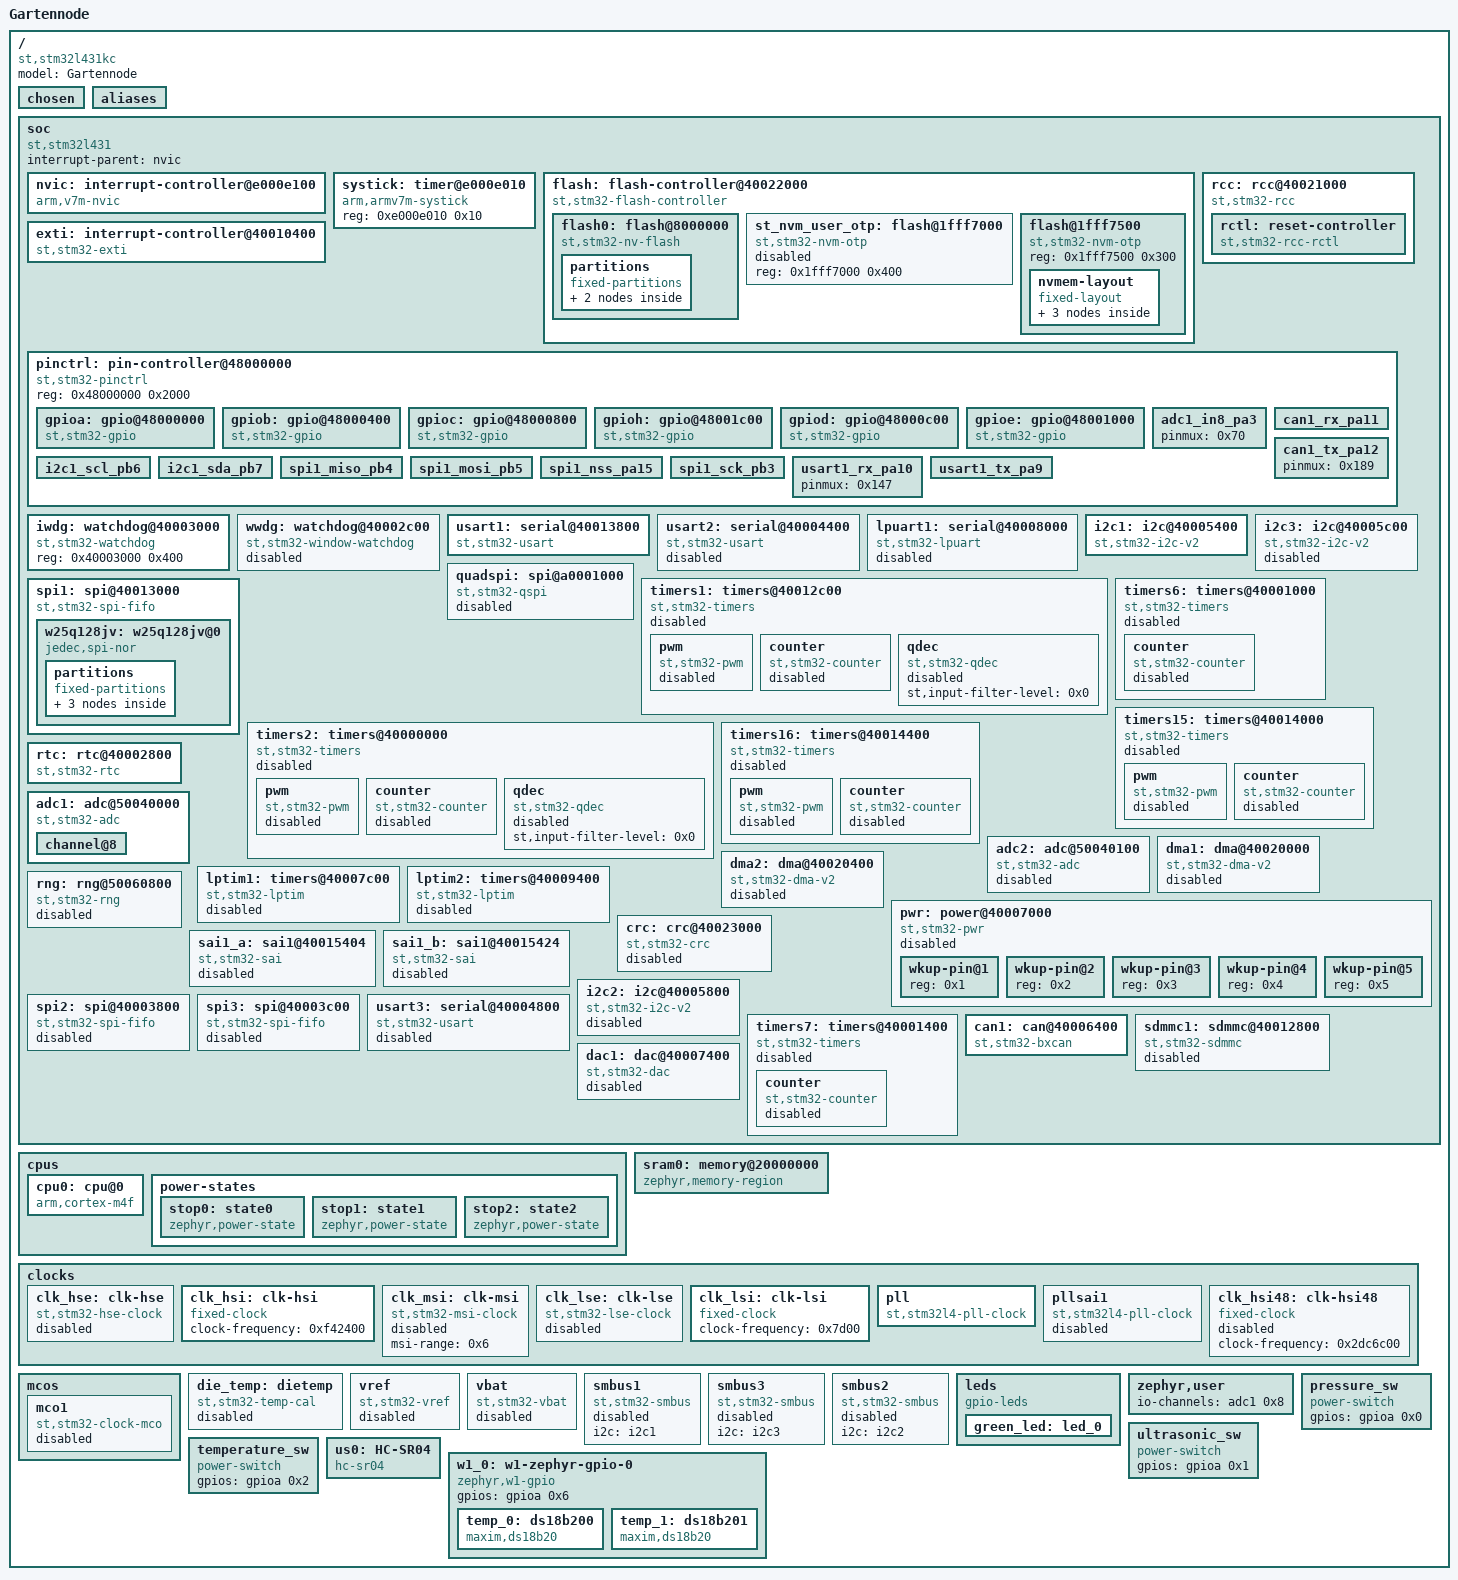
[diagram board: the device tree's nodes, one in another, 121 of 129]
/dts-v1/;

/* node '/' defined in zephyr/dts/common/skeleton.dtsi:9 */
/ {
	#address-cells = < 0x1 >;      /* in zephyr/dts/common/skeleton.dtsi:10 */
	#size-cells = < 0x1 >;         /* in zephyr/dts/common/skeleton.dtsi:11 */
	model = "Gartennode";          /* in application/boards/st/gartennode/gartennode.dts:6 */
	compatible = "st,stm32l431kc"; /* in application/boards/st/gartennode/gartennode.dts:7 */

	/* node '/chosen' defined in zephyr/dts/common/skeleton.dtsi:13 */
	chosen {
		zephyr,crc = &crc;                              /* in zephyr/dts/arm/st/l4/stm32l4.dtsi:25 */
		zephyr,entropy = &rng;                          /* in zephyr/dts/arm/st/l4/stm32l4.dtsi:26 */
		zephyr,flash-controller = &flash;               /* in zephyr/dts/arm/st/l4/stm32l4.dtsi:27 */
		zephyr,console = &usart1;                       /* in application/boards/st/gartennode/gartennode.dts:10 */
		zephyr,shell-uart = &usart1;                    /* in application/boards/st/gartennode/gartennode.dts:11 */
		zephyr,sram = &sram0;                           /* in application/boards/st/gartennode/gartennode.dts:12 */
		zephyr,flash = &flash0;                         /* in application/boards/st/gartennode/gartennode.dts:13 */
		zephyr,code-partition = &slot0_partition;       /* in application/boards/st/gartennode/gartennode.dts:14 */
		zephyr,canbus = &can1;                          /* in application/boards/st/gartennode/gartennode.dts:15 */
		zephyr,settings-partition = &storage_partition; /* in application/boards/st/gartennode/gartennode.dts:16 */
	};

	/* node '/aliases' defined in zephyr/dts/common/skeleton.dtsi:15 */
	aliases {
		led0 = &green_led;      /* in application/boards/st/gartennode/gartennode.dts:28 */
		green-led = &green_led; /* in application/boards/gartennode.overlay:34 */
	};

	/* node '/soc' defined in zephyr/dts/arm/armv7-m.dtsi:6 */
	soc {
		#address-cells = < 0x1 >;     /* in zephyr/dts/arm/armv7-m.dtsi:7 */
		#size-cells = < 0x1 >;        /* in zephyr/dts/arm/armv7-m.dtsi:8 */
		interrupt-parent = < &nvic >; /* in zephyr/dts/arm/armv7-m.dtsi:10 */
		ranges;                       /* in zephyr/dts/arm/armv7-m.dtsi:11 */
		compatible = "st,stm32l431",
		             "st,stm32l4",
		             "simple-bus";    /* in zephyr/dts/arm/st/l4/stm32l431.dtsi:21 */

		/* node '/soc/interrupt-controller@e000e100' defined in zephyr/dts/arm/armv7-m.dtsi:13 */
		nvic: interrupt-controller@e000e100 {
			#address-cells = < 0x1 >;            /* in zephyr/dts/arm/armv7-m.dtsi:14 */
			compatible = "arm,v7m-nvic";         /* in zephyr/dts/arm/armv7-m.dtsi:15 */
			reg = < 0xe000e100 0xc00 >;          /* in zephyr/dts/arm/armv7-m.dtsi:16 */
			interrupt-controller;                /* in zephyr/dts/arm/armv7-m.dtsi:17 */
			#interrupt-cells = < 0x2 >;          /* in zephyr/dts/arm/armv7-m.dtsi:18 */
			arm,num-irq-priority-bits = < 0x4 >; /* in zephyr/dts/arm/st/l4/stm32l4.dtsi:645 */
			phandle = < 0x1 >;                   /* in zephyr/dts/arm/armv7-m.dtsi:10 */
		};

		/* node '/soc/timer@e000e010' defined in zephyr/dts/arm/armv7-m.dtsi:21 */
		systick: timer@e000e010 {
			compatible = "arm,armv7m-systick"; /* in zephyr/dts/arm/armv7-m.dtsi:22 */
			reg = < 0xe000e010 0x10 >;         /* in zephyr/dts/arm/armv7-m.dtsi:23 */
		};

		/* node '/soc/flash-controller@40022000' defined in zephyr/dts/arm/st/l4/stm32l4.dtsi:128 */
		flash: flash-controller@40022000 {
			compatible = "st,stm32-flash-controller",
			             "st,stm32l4-flash-controller"; /* in zephyr/dts/arm/st/l4/stm32l4.dtsi:129 */
			reg = < 0x40022000 0x400 >;                 /* in zephyr/dts/arm/st/l4/stm32l4.dtsi:130 */
			interrupts = < 0x4 0x0 >;                   /* in zephyr/dts/arm/st/l4/stm32l4.dtsi:131 */
			clocks = < &rcc 0x48 0x100 >;               /* in zephyr/dts/arm/st/l4/stm32l4.dtsi:132 */
			#address-cells = < 0x1 >;                   /* in zephyr/dts/arm/st/l4/stm32l4.dtsi:134 */
			#size-cells = < 0x1 >;                      /* in zephyr/dts/arm/st/l4/stm32l4.dtsi:135 */

			/* node '/soc/flash-controller@40022000/flash@8000000' defined in zephyr/dts/arm/st/l4/stm32l4.dtsi:137 */
			flash0: flash@8000000 {
				compatible = "st,stm32-nv-flash",
				             "soc-nv-flash";      /* in zephyr/dts/arm/st/l4/stm32l4.dtsi:138 */
				write-block-size = < 0x8 >;       /* in zephyr/dts/arm/st/l4/stm32l4.dtsi:140 */
				erase-block-size = < 0x800 >;     /* in zephyr/dts/arm/st/l4/stm32l4.dtsi:141 */
				max-erase-time = < 0x19 >;        /* in zephyr/dts/arm/st/l4/stm32l4.dtsi:143 */
				reg = < 0x8000000 0x40000 >;      /* in application/boards/st/gartennode/stm32l431Xc.dtsi:18 */

				/* node '/soc/flash-controller@40022000/flash@8000000/partitions' defined in application/boards/st/gartennode/gartennode.dts:128 */
				partitions {
					compatible = "fixed-partitions"; /* in application/boards/st/gartennode/gartennode.dts:129 */
					#address-cells = < 0x1 >;        /* in application/boards/st/gartennode/gartennode.dts:130 */
					#size-cells = < 0x1 >;           /* in application/boards/st/gartennode/gartennode.dts:131 */

					/* node '/soc/flash-controller@40022000/flash@8000000/partitions/partition@0' defined in application/boards/st/gartennode/gartennode.dts:137 */
					boot_partition: partition@0 {
						label = "mcuboot";     /* in application/boards/st/gartennode/gartennode.dts:138 */
						reg = < 0x0 0x10000 >; /* in application/boards/st/gartennode/gartennode.dts:139 */
						read-only;             /* in application/boards/st/gartennode/gartennode.dts:140 */
					};

					/* node '/soc/flash-controller@40022000/flash@8000000/partitions/partition@10000' defined in application/boards/st/gartennode/gartennode.dts:146 */
					slot0_partition: partition@10000 {
						label = "image-0";         /* in application/boards/st/gartennode/gartennode.dts:147 */
						reg = < 0x10000 0x30000 >; /* in application/boards/st/gartennode/gartennode.dts:148 */
					};
				};
			};

			/* node '/soc/flash-controller@40022000/flash@1fff7000' defined in zephyr/dts/arm/st/l4/stm32l4.dtsi:146 */
			st_nvm_user_otp: flash@1fff7000 {
				compatible = "st,stm32-nvm-otp"; /* in zephyr/dts/arm/st/l4/stm32l4.dtsi:147 */
				reg = < 0x1fff7000 0x400 >;      /* in zephyr/dts/arm/st/l4/stm32l4.dtsi:148 */
				status = "disabled";             /* in zephyr/dts/arm/st/l4/stm32l4.dtsi:149 */
			};

			/* node '/soc/flash-controller@40022000/flash@1fff7500' defined in zephyr/dts/arm/st/l4/stm32l4.dtsi:153 */
			flash@1fff7500 {
				compatible = "st,stm32-nvm-otp"; /* in zephyr/dts/arm/st/l4/stm32l4.dtsi:154 */
				reg = < 0x1fff7500 0x300 >;      /* in zephyr/dts/arm/st/l4/stm32l4.dtsi:155 */

				/* node '/soc/flash-controller@40022000/flash@1fff7500/nvmem-layout' defined in zephyr/dts/arm/st/l4/stm32l4.dtsi:157 */
				nvmem-layout {
					compatible = "fixed-layout"; /* in zephyr/dts/arm/st/l4/stm32l4.dtsi:158 */
					#address-cells = < 0x1 >;    /* in zephyr/dts/arm/st/l4/stm32l4.dtsi:159 */
					#size-cells = < 0x1 >;       /* in zephyr/dts/arm/st/l4/stm32l4.dtsi:160 */

					/* node '/soc/flash-controller@40022000/flash@1fff7500/nvmem-layout/ts-cal1@a8' defined in zephyr/dts/arm/st/l4/stm32l4.dtsi:162 */
					ts_cal1_otp: ts-cal1@a8 {
						reg = < 0xa8 0x2 >;          /* in zephyr/dts/arm/st/l4/stm32l4.dtsi:163 */
						#nvmem-cell-cells = < 0x0 >; /* in zephyr/dts/arm/st/l4/stm32l4.dtsi:164 */
						read-only;                   /* in zephyr/dts/arm/st/l4/stm32l4.dtsi:165 */
						phandle = < 0x16 >;          /* in zephyr/dts/arm/st/l4/stm32l4.dtsi:603 */
					};

					/* node '/soc/flash-controller@40022000/flash@1fff7500/nvmem-layout/vrefint@aa' defined in zephyr/dts/arm/st/l4/stm32l4.dtsi:168 */
					vrefint_otp: vrefint@aa {
						reg = < 0xaa 0x2 >;          /* in zephyr/dts/arm/st/l4/stm32l4.dtsi:169 */
						#nvmem-cell-cells = < 0x0 >; /* in zephyr/dts/arm/st/l4/stm32l4.dtsi:170 */
						read-only;                   /* in zephyr/dts/arm/st/l4/stm32l4.dtsi:171 */
						phandle = < 0x19 >;          /* in zephyr/dts/arm/st/l4/stm32l4.dtsi:614 */
					};

					/* node '/soc/flash-controller@40022000/flash@1fff7500/nvmem-layout/ts-cal2@ca' defined in zephyr/dts/arm/st/l4/stm32l4.dtsi:174 */
					ts_cal2_otp: ts-cal2@ca {
						reg = < 0xca 0x2 >;          /* in zephyr/dts/arm/st/l4/stm32l4.dtsi:175 */
						#nvmem-cell-cells = < 0x0 >; /* in zephyr/dts/arm/st/l4/stm32l4.dtsi:176 */
						read-only;                   /* in zephyr/dts/arm/st/l4/stm32l4.dtsi:177 */
						phandle = < 0x17 >;          /* in zephyr/dts/arm/st/l4/stm32l4.dtsi:603 */
					};
				};
			};
		};

		/* node '/soc/rcc@40021000' defined in zephyr/dts/arm/st/l4/stm32l4.dtsi:183 */
		rcc: rcc@40021000 {
			compatible = "st,stm32-rcc";     /* in zephyr/dts/arm/st/l4/stm32l4.dtsi:184 */
			#clock-cells = < 0x2 >;          /* in zephyr/dts/arm/st/l4/stm32l4.dtsi:185 */
			reg = < 0x40021000 0x400 >;      /* in zephyr/dts/arm/st/l4/stm32l4.dtsi:186 */
			clocks = < &pll >;               /* in application/boards/st/gartennode/gartennode.dts:59 */
			clock-frequency = < 0x4c4b400 >; /* in application/boards/st/gartennode/gartennode.dts:60 */
			ahb-prescaler = < 0x1 >;         /* in application/boards/st/gartennode/gartennode.dts:61 */
			apb1-prescaler = < 0x1 >;        /* in application/boards/st/gartennode/gartennode.dts:62 */
			apb2-prescaler = < 0x1 >;        /* in application/boards/st/gartennode/gartennode.dts:63 */
			phandle = < 0x2 >;               /* in zephyr/dts/arm/st/l4/stm32l4.dtsi:132 */

			/* node '/soc/rcc@40021000/reset-controller' defined in zephyr/dts/arm/st/l4/stm32l4.dtsi:188 */
			rctl: reset-controller {
				compatible = "st,stm32-rcc-rctl"; /* in zephyr/dts/arm/st/l4/stm32l4.dtsi:189 */
				#reset-cells = < 0x1 >;           /* in zephyr/dts/arm/st/l4/stm32l4.dtsi:190 */
				phandle = < 0x4 >;                /* in zephyr/dts/arm/st/l4/stm32l4.dtsi:267 */
			};
		};

		/* node '/soc/interrupt-controller@40010400' defined in zephyr/dts/arm/st/l4/stm32l4.dtsi:194 */
		exti: interrupt-controller@40010400 {
			compatible = "st,stm32-exti";  /* in zephyr/dts/arm/st/l4/stm32l4.dtsi:195 */
			interrupt-controller;          /* in zephyr/dts/arm/st/l4/stm32l4.dtsi:196 */
			#interrupt-cells = < 0x1 >;    /* in zephyr/dts/arm/st/l4/stm32l4.dtsi:197 */
			#address-cells = < 0x0 >;      /* in zephyr/dts/arm/st/l4/stm32l4.dtsi:198 */
			reg = < 0x40010400 0x400 >;    /* in zephyr/dts/arm/st/l4/stm32l4.dtsi:199 */
			clocks = < &rcc 0x60 0x1 >;    /* in zephyr/dts/arm/st/l4/stm32l4.dtsi:200 */
			num-lines = < 0x40 >;          /* in zephyr/dts/arm/st/l4/stm32l4.dtsi:201 */
			interrupts = < 0x6 0x0 >,
			             < 0x7 0x0 >,
			             < 0x8 0x0 >,
			             < 0x9 0x0 >,
			             < 0xa 0x0 >,
			             < 0x17 0x0 >,
			             < 0x28 0x0 >;     /* in zephyr/dts/arm/st/l4/stm32l4.dtsi:202 */
			interrupt-names = "line0",
			                  "line1",
			                  "line2",
			                  "line3",
			                  "line4",
			                  "line5-9",
			                  "line10-15"; /* in zephyr/dts/arm/st/l4/stm32l4.dtsi:204 */
			line-ranges = < 0x0 0x1 >,
			              < 0x1 0x1 >,
			              < 0x2 0x1 >,
			              < 0x3 0x1 >,
			              < 0x4 0x1 >,
			              < 0x5 0x5 >,
			              < 0xa 0x6 >;     /* in zephyr/dts/arm/st/l4/stm32l4.dtsi:206 */
		};

		/* node '/soc/pin-controller@48000000' defined in zephyr/dts/arm/st/l4/stm32l4.dtsi:210 */
		pinctrl: pin-controller@48000000 {
			compatible = "st,stm32-pinctrl"; /* in zephyr/dts/arm/st/l4/stm32l4.dtsi:211 */
			#address-cells = < 0x1 >;        /* in zephyr/dts/arm/st/l4/stm32l4.dtsi:212 */
			#size-cells = < 0x1 >;           /* in zephyr/dts/arm/st/l4/stm32l4.dtsi:213 */
			reg = < 0x48000000 0x2000 >;     /* in zephyr/dts/arm/st/l4/stm32l4.dtsi:214 */

			/* node '/soc/pin-controller@48000000/gpio@48000000' defined in zephyr/dts/arm/st/l4/stm32l4.dtsi:216 */
			gpioa: gpio@48000000 {
				compatible = "st,stm32-gpio"; /* in zephyr/dts/arm/st/l4/stm32l4.dtsi:217 */
				gpio-controller;              /* in zephyr/dts/arm/st/l4/stm32l4.dtsi:218 */
				#gpio-cells = < 0x2 >;        /* in zephyr/dts/arm/st/l4/stm32l4.dtsi:219 */
				reg = < 0x48000000 0x400 >;   /* in zephyr/dts/arm/st/l4/stm32l4.dtsi:220 */
				clocks = < &rcc 0x4c 0x1 >;   /* in zephyr/dts/arm/st/l4/stm32l4.dtsi:221 */
				phandle = < 0xd >;            /* in application/boards/st/gartennode/gartennode.dts:83 */
			};

			/* node '/soc/pin-controller@48000000/gpio@48000400' defined in zephyr/dts/arm/st/l4/stm32l4.dtsi:224 */
			gpiob: gpio@48000400 {
				compatible = "st,stm32-gpio"; /* in zephyr/dts/arm/st/l4/stm32l4.dtsi:225 */
				gpio-controller;              /* in zephyr/dts/arm/st/l4/stm32l4.dtsi:226 */
				#gpio-cells = < 0x2 >;        /* in zephyr/dts/arm/st/l4/stm32l4.dtsi:227 */
				reg = < 0x48000400 0x400 >;   /* in zephyr/dts/arm/st/l4/stm32l4.dtsi:228 */
				clocks = < &rcc 0x4c 0x2 >;   /* in zephyr/dts/arm/st/l4/stm32l4.dtsi:229 */
			};

			/* node '/soc/pin-controller@48000000/gpio@48000800' defined in zephyr/dts/arm/st/l4/stm32l4.dtsi:232 */
			gpioc: gpio@48000800 {
				compatible = "st,stm32-gpio"; /* in zephyr/dts/arm/st/l4/stm32l4.dtsi:233 */
				gpio-controller;              /* in zephyr/dts/arm/st/l4/stm32l4.dtsi:234 */
				#gpio-cells = < 0x2 >;        /* in zephyr/dts/arm/st/l4/stm32l4.dtsi:235 */
				reg = < 0x48000800 0x400 >;   /* in zephyr/dts/arm/st/l4/stm32l4.dtsi:236 */
				clocks = < &rcc 0x4c 0x4 >;   /* in zephyr/dts/arm/st/l4/stm32l4.dtsi:237 */
				phandle = < 0x1d >;           /* in application/boards/st/gartennode/gartennode.dts:22 */
			};

			/* node '/soc/pin-controller@48000000/gpio@48001c00' defined in zephyr/dts/arm/st/l4/stm32l4.dtsi:240 */
			gpioh: gpio@48001c00 {
				compatible = "st,stm32-gpio"; /* in zephyr/dts/arm/st/l4/stm32l4.dtsi:241 */
				gpio-controller;              /* in zephyr/dts/arm/st/l4/stm32l4.dtsi:242 */
				#gpio-cells = < 0x2 >;        /* in zephyr/dts/arm/st/l4/stm32l4.dtsi:243 */
				reg = < 0x48001c00 0x400 >;   /* in zephyr/dts/arm/st/l4/stm32l4.dtsi:244 */
				clocks = < &rcc 0x4c 0x80 >;  /* in zephyr/dts/arm/st/l4/stm32l4.dtsi:245 */
			};

			/* node '/soc/pin-controller@48000000/gpio@48000c00' defined in zephyr/dts/arm/st/l4/stm32l431.dtsi:24 */
			gpiod: gpio@48000c00 {
				compatible = "st,stm32-gpio"; /* in zephyr/dts/arm/st/l4/stm32l431.dtsi:25 */
				reg = < 0x48000c00 0x400 >;   /* in zephyr/dts/arm/st/l4/stm32l431.dtsi:26 */
				clocks = < &rcc 0x4c 0x8 >;   /* in zephyr/dts/arm/st/l4/stm32l431.dtsi:27 */
				gpio-controller;              /* in zephyr/dts/arm/st/l4/stm32l431.dtsi:28 */
				#gpio-cells = < 0x2 >;        /* in zephyr/dts/arm/st/l4/stm32l431.dtsi:29 */
			};

			/* node '/soc/pin-controller@48000000/gpio@48001000' defined in zephyr/dts/arm/st/l4/stm32l431.dtsi:32 */
			gpioe: gpio@48001000 {
				compatible = "st,stm32-gpio"; /* in zephyr/dts/arm/st/l4/stm32l431.dtsi:33 */
				reg = < 0x48001000 0x400 >;   /* in zephyr/dts/arm/st/l4/stm32l431.dtsi:34 */
				clocks = < &rcc 0x4c 0x10 >;  /* in zephyr/dts/arm/st/l4/stm32l431.dtsi:35 */
				gpio-controller;              /* in zephyr/dts/arm/st/l4/stm32l431.dtsi:36 */
				#gpio-cells = < 0x2 >;        /* in zephyr/dts/arm/st/l4/stm32l431.dtsi:37 */
			};

			/* node '/soc/pin-controller@48000000/adc1_in8_pa3' defined in modules/hal/stm32/dts/st/l4/stm32l431k(b-c)ux-pinctrl.dtsi:25 */
			adc1_in8_pa3: adc1_in8_pa3 {
				pinmux = < 0x70 >; /* in modules/hal/stm32/dts/st/l4/stm32l431k(b-c)ux-pinctrl.dtsi:26 */
				phandle = < 0xe >; /* in application/boards/gartennode.overlay:67 */
			};

			/* node '/soc/pin-controller@48000000/can1_rx_pa11' defined in modules/hal/stm32/dts/st/l4/stm32l431k(b-c)ux-pinctrl.dtsi:161 */
			can1_rx_pa11: can1_rx_pa11 {
				pinmux = < 0x169 >; /* in modules/hal/stm32/dts/st/l4/stm32l431k(b-c)ux-pinctrl.dtsi:162 */
				bias-pull-up;       /* in modules/hal/stm32/dts/st/l4/stm32l431k(b-c)ux-pinctrl.dtsi:163 */
				phandle = < 0x10 >; /* in application/boards/st/gartennode/gartennode.dts:116 */
			};

			/* node '/soc/pin-controller@48000000/can1_tx_pa12' defined in modules/hal/stm32/dts/st/l4/stm32l431k(b-c)ux-pinctrl.dtsi:168 */
			can1_tx_pa12: can1_tx_pa12 {
				pinmux = < 0x189 >; /* in modules/hal/stm32/dts/st/l4/stm32l431k(b-c)ux-pinctrl.dtsi:169 */
				phandle = < 0x11 >; /* in application/boards/st/gartennode/gartennode.dts:116 */
			};

			/* node '/soc/pin-controller@48000000/i2c1_scl_pb6' defined in modules/hal/stm32/dts/st/l4/stm32l431k(b-c)ux-pinctrl.dtsi:274 */
			i2c1_scl_pb6: i2c1_scl_pb6 {
				pinmux = < 0x2c4 >; /* in modules/hal/stm32/dts/st/l4/stm32l431k(b-c)ux-pinctrl.dtsi:275 */
				bias-pull-up;       /* in modules/hal/stm32/dts/st/l4/stm32l431k(b-c)ux-pinctrl.dtsi:276 */
				drive-open-drain;   /* in modules/hal/stm32/dts/st/l4/stm32l431k(b-c)ux-pinctrl.dtsi:277 */
				phandle = < 0x7 >;  /* in application/boards/st/gartennode/gartennode.dts:109 */
			};

			/* node '/soc/pin-controller@48000000/i2c1_sda_pb7' defined in modules/hal/stm32/dts/st/l4/stm32l431k(b-c)ux-pinctrl.dtsi:294 */
			i2c1_sda_pb7: i2c1_sda_pb7 {
				pinmux = < 0x2e4 >; /* in modules/hal/stm32/dts/st/l4/stm32l431k(b-c)ux-pinctrl.dtsi:295 */
				bias-pull-up;       /* in modules/hal/stm32/dts/st/l4/stm32l431k(b-c)ux-pinctrl.dtsi:296 */
				drive-open-drain;   /* in modules/hal/stm32/dts/st/l4/stm32l431k(b-c)ux-pinctrl.dtsi:297 */
				phandle = < 0x8 >;  /* in application/boards/st/gartennode/gartennode.dts:109 */
			};

			/* node '/soc/pin-controller@48000000/spi1_miso_pb4' defined in modules/hal/stm32/dts/st/l4/stm32l431k(b-c)ux-pinctrl.dtsi:500 */
			spi1_miso_pb4: spi1_miso_pb4 {
				pinmux = < 0x285 >;            /* in modules/hal/stm32/dts/st/l4/stm32l431k(b-c)ux-pinctrl.dtsi:501 */
				bias-pull-down;                /* in modules/hal/stm32/dts/st/l4/stm32l431k(b-c)ux-pinctrl.dtsi:502 */
				slew-rate = "very-high-speed"; /* in modules/hal/stm32/dts/st/l4/stm32l431k(b-c)ux-pinctrl.dtsi:503 */
				phandle = < 0xb >;             /* in application/boards/st/gartennode/gartennode.dts:74 */
			};

			/* node '/soc/pin-controller@48000000/spi1_mosi_pb5' defined in modules/hal/stm32/dts/st/l4/stm32l431k(b-c)ux-pinctrl.dtsi:526 */
			spi1_mosi_pb5: spi1_mosi_pb5 {
				pinmux = < 0x2a5 >;            /* in modules/hal/stm32/dts/st/l4/stm32l431k(b-c)ux-pinctrl.dtsi:527 */
				bias-pull-down;                /* in modules/hal/stm32/dts/st/l4/stm32l431k(b-c)ux-pinctrl.dtsi:528 */
				slew-rate = "very-high-speed"; /* in modules/hal/stm32/dts/st/l4/stm32l431k(b-c)ux-pinctrl.dtsi:529 */
				phandle = < 0xc >;             /* in application/boards/st/gartennode/gartennode.dts:74 */
			};

			/* node '/soc/pin-controller@48000000/spi1_nss_pa15' defined in modules/hal/stm32/dts/st/l4/stm32l431k(b-c)ux-pinctrl.dtsi:546 */
			spi1_nss_pa15: spi1_nss_pa15 {
				pinmux = < 0x1e5 >;            /* in modules/hal/stm32/dts/st/l4/stm32l431k(b-c)ux-pinctrl.dtsi:547 */
				bias-pull-up;                  /* in modules/hal/stm32/dts/st/l4/stm32l431k(b-c)ux-pinctrl.dtsi:548 */
				slew-rate = "very-high-speed"; /* in modules/hal/stm32/dts/st/l4/stm32l431k(b-c)ux-pinctrl.dtsi:549 */
				phandle = < 0x9 >;             /* in application/boards/st/gartennode/gartennode.dts:74 */
			};

			/* node '/soc/pin-controller@48000000/spi1_sck_pb3' defined in modules/hal/stm32/dts/st/l4/stm32l431k(b-c)ux-pinctrl.dtsi:584 */
			spi1_sck_pb3: spi1_sck_pb3 {
				pinmux = < 0x265 >;            /* in modules/hal/stm32/dts/st/l4/stm32l431k(b-c)ux-pinctrl.dtsi:585 */
				bias-pull-down;                /* in modules/hal/stm32/dts/st/l4/stm32l431k(b-c)ux-pinctrl.dtsi:586 */
				slew-rate = "very-high-speed"; /* in modules/hal/stm32/dts/st/l4/stm32l431k(b-c)ux-pinctrl.dtsi:587 */
				phandle = < 0xa >;             /* in application/boards/st/gartennode/gartennode.dts:74 */
			};

			/* node '/soc/pin-controller@48000000/usart1_rx_pa10' defined in modules/hal/stm32/dts/st/l4/stm32l431k(b-c)ux-pinctrl.dtsi:782 */
			usart1_rx_pa10: usart1_rx_pa10 {
				pinmux = < 0x147 >; /* in modules/hal/stm32/dts/st/l4/stm32l431k(b-c)ux-pinctrl.dtsi:783 */
				phandle = < 0x6 >;  /* in application/boards/st/gartennode/gartennode.dts:67 */
			};

			/* node '/soc/pin-controller@48000000/usart1_tx_pa9' defined in modules/hal/stm32/dts/st/l4/stm32l431k(b-c)ux-pinctrl.dtsi:805 */
			usart1_tx_pa9: usart1_tx_pa9 {
				pinmux = < 0x127 >; /* in modules/hal/stm32/dts/st/l4/stm32l431k(b-c)ux-pinctrl.dtsi:806 */
				bias-pull-up;       /* in modules/hal/stm32/dts/st/l4/stm32l431k(b-c)ux-pinctrl.dtsi:807 */
				phandle = < 0x5 >;  /* in application/boards/st/gartennode/gartennode.dts:67 */
			};
		};

		/* node '/soc/watchdog@40003000' defined in zephyr/dts/arm/st/l4/stm32l4.dtsi:249 */
		iwdg: watchdog@40003000 {
			compatible = "st,stm32-watchdog"; /* in zephyr/dts/arm/st/l4/stm32l4.dtsi:250 */
			reg = < 0x40003000 0x400 >;       /* in zephyr/dts/arm/st/l4/stm32l4.dtsi:251 */
			status = "okay";                  /* in application/boards/st/gartennode/gartennode.dts:37 */
		};

		/* node '/soc/watchdog@40002c00' defined in zephyr/dts/arm/st/l4/stm32l4.dtsi:255 */
		wwdg: watchdog@40002c00 {
			compatible = "st,stm32-window-watchdog"; /* in zephyr/dts/arm/st/l4/stm32l4.dtsi:256 */
			reg = < 0x40002c00 0x400 >;              /* in zephyr/dts/arm/st/l4/stm32l4.dtsi:257 */
			clocks = < &rcc 0x58 0x800 >;            /* in zephyr/dts/arm/st/l4/stm32l4.dtsi:258 */
			interrupts = < 0x0 0x7 >;                /* in zephyr/dts/arm/st/l4/stm32l4.dtsi:259 */
			status = "disabled";                     /* in application/boards/st/gartennode/gartennode.dts:33 */
		};

		/* node '/soc/serial@40013800' defined in zephyr/dts/arm/st/l4/stm32l4.dtsi:263 */
		usart1: serial@40013800 {
			compatible = "st,stm32-usart",
			             "st,stm32-uart";                   /* in zephyr/dts/arm/st/l4/stm32l4.dtsi:264 */
			reg = < 0x40013800 0x400 >;                     /* in zephyr/dts/arm/st/l4/stm32l4.dtsi:265 */
			clocks = < &rcc 0x60 0x4000 >;                  /* in zephyr/dts/arm/st/l4/stm32l4.dtsi:266 */
			resets = < &rctl 0x80e >;                       /* in zephyr/dts/arm/st/l4/stm32l4.dtsi:267 */
			interrupts = < 0x25 0x0 >;                      /* in zephyr/dts/arm/st/l4/stm32l4.dtsi:268 */
			pinctrl-0 = < &usart1_tx_pa9 &usart1_rx_pa10 >; /* in application/boards/st/gartennode/gartennode.dts:67 */
			pinctrl-names = "default";                      /* in application/boards/st/gartennode/gartennode.dts:68 */
			current-speed = < 0x1c200 >;                    /* in application/boards/st/gartennode/gartennode.dts:69 */
			status = "okay";                                /* in application/boards/st/gartennode/gartennode.dts:70 */
		};

		/* node '/soc/serial@40004400' defined in zephyr/dts/arm/st/l4/stm32l4.dtsi:272 */
		usart2: serial@40004400 {
			compatible = "st,stm32-usart",
			             "st,stm32-uart";   /* in zephyr/dts/arm/st/l4/stm32l4.dtsi:273 */
			reg = < 0x40004400 0x400 >;     /* in zephyr/dts/arm/st/l4/stm32l4.dtsi:274 */
			clocks = < &rcc 0x58 0x20000 >; /* in zephyr/dts/arm/st/l4/stm32l4.dtsi:275 */
			resets = < &rctl 0x711 >;       /* in zephyr/dts/arm/st/l4/stm32l4.dtsi:276 */
			interrupts = < 0x26 0x0 >;      /* in zephyr/dts/arm/st/l4/stm32l4.dtsi:277 */
			status = "disabled";            /* in zephyr/dts/arm/st/l4/stm32l4.dtsi:278 */
		};

		/* node '/soc/serial@40008000' defined in zephyr/dts/arm/st/l4/stm32l4.dtsi:281 */
		lpuart1: serial@40008000 {
			compatible = "st,stm32-lpuart",
			             "st,stm32-uart";   /* in zephyr/dts/arm/st/l4/stm32l4.dtsi:282 */
			reg = < 0x40008000 0x400 >;     /* in zephyr/dts/arm/st/l4/stm32l4.dtsi:283 */
			clocks = < &rcc 0x5c 0x1 >;     /* in zephyr/dts/arm/st/l4/stm32l4.dtsi:284 */
			resets = < &rctl 0x780 >;       /* in zephyr/dts/arm/st/l4/stm32l4.dtsi:285 */
			interrupts = < 0x46 0x0 >;      /* in zephyr/dts/arm/st/l4/stm32l4.dtsi:286 */
			status = "disabled";            /* in zephyr/dts/arm/st/l4/stm32l4.dtsi:287 */
		};

		/* node '/soc/i2c@40005400' defined in zephyr/dts/arm/st/l4/stm32l4.dtsi:290 */
		i2c1: i2c@40005400 {
			compatible = "st,stm32-i2c-v2";              /* in zephyr/dts/arm/st/l4/stm32l4.dtsi:291 */
			#address-cells = < 0x1 >;                    /* in zephyr/dts/arm/st/l4/stm32l4.dtsi:293 */
			#size-cells = < 0x0 >;                       /* in zephyr/dts/arm/st/l4/stm32l4.dtsi:294 */
			reg = < 0x40005400 0x400 >;                  /* in zephyr/dts/arm/st/l4/stm32l4.dtsi:295 */
			clocks = < &rcc 0x58 0x200000 >;             /* in zephyr/dts/arm/st/l4/stm32l4.dtsi:296 */
			interrupts = < 0x1f 0x0 >,
			             < 0x20 0x0 >;                   /* in zephyr/dts/arm/st/l4/stm32l4.dtsi:297 */
			interrupt-names = "event",
			                  "error";                   /* in zephyr/dts/arm/st/l4/stm32l4.dtsi:298 */
			pinctrl-0 = < &i2c1_scl_pb6 &i2c1_sda_pb7 >; /* in application/boards/st/gartennode/gartennode.dts:109 */
			pinctrl-names = "default";                   /* in application/boards/st/gartennode/gartennode.dts:110 */
			clock-frequency = < 0x61a80 >;               /* in application/boards/st/gartennode/gartennode.dts:111 */
			status = "okay";                             /* in application/boards/st/gartennode/gartennode.dts:112 */
			phandle = < 0x1a >;                          /* in zephyr/dts/arm/st/l4/stm32l4.dtsi:631 */
		};

		/* node '/soc/i2c@40005c00' defined in zephyr/dts/arm/st/l4/stm32l4.dtsi:302 */
		i2c3: i2c@40005c00 {
			compatible = "st,stm32-i2c-v2";  /* in zephyr/dts/arm/st/l4/stm32l4.dtsi:303 */
			clock-frequency = < 0x186a0 >;   /* in zephyr/dts/arm/st/l4/stm32l4.dtsi:304 */
			#address-cells = < 0x1 >;        /* in zephyr/dts/arm/st/l4/stm32l4.dtsi:305 */
			#size-cells = < 0x0 >;           /* in zephyr/dts/arm/st/l4/stm32l4.dtsi:306 */
			reg = < 0x40005c00 0x400 >;      /* in zephyr/dts/arm/st/l4/stm32l4.dtsi:307 */
			clocks = < &rcc 0x58 0x800000 >; /* in zephyr/dts/arm/st/l4/stm32l4.dtsi:308 */
			interrupts = < 0x48 0x0 >,
			             < 0x49 0x0 >;       /* in zephyr/dts/arm/st/l4/stm32l4.dtsi:309 */
			interrupt-names = "event",
			                  "error";       /* in zephyr/dts/arm/st/l4/stm32l4.dtsi:310 */
			status = "disabled";             /* in zephyr/dts/arm/st/l4/stm32l4.dtsi:311 */
			phandle = < 0x1b >;              /* in zephyr/dts/arm/st/l4/stm32l4.dtsi:639 */
		};

		/* node '/soc/spi@a0001000' defined in zephyr/dts/arm/st/l4/stm32l4.dtsi:314 */
		quadspi: spi@a0001000 {
			compatible = "st,stm32-qspi";    /* in zephyr/dts/arm/st/l4/stm32l4.dtsi:315 */
			#address-cells = < 0x1 >;        /* in zephyr/dts/arm/st/l4/stm32l4.dtsi:316 */
			#size-cells = < 0x0 >;           /* in zephyr/dts/arm/st/l4/stm32l4.dtsi:317 */
			reg = < 0xa0001000 0x400 >,
			      < 0x90000000 0x10000000 >; /* in zephyr/dts/arm/st/l4/stm32l4.dtsi:318 */
			interrupts = < 0x47 0x0 >;       /* in zephyr/dts/arm/st/l4/stm32l4.dtsi:319 */
			clocks = < &rcc 0x50 0x100 >;    /* in zephyr/dts/arm/st/l4/stm32l4.dtsi:320 */
			status = "disabled";             /* in zephyr/dts/arm/st/l4/stm32l4.dtsi:321 */
		};

		/* node '/soc/spi@40013000' defined in zephyr/dts/arm/st/l4/stm32l4.dtsi:324 */
		spi1: spi@40013000 {
			compatible = "st,stm32-spi-fifo",
			             "st,stm32-spi";                                                /* in zephyr/dts/arm/st/l4/stm32l4.dtsi:325 */
			#address-cells = < 0x1 >;                                                   /* in zephyr/dts/arm/st/l4/stm32l4.dtsi:326 */
			#size-cells = < 0x0 >;                                                      /* in zephyr/dts/arm/st/l4/stm32l4.dtsi:327 */
			reg = < 0x40013000 0x400 >;                                                 /* in zephyr/dts/arm/st/l4/stm32l4.dtsi:328 */
			interrupts = < 0x23 0x5 >;                                                  /* in zephyr/dts/arm/st/l4/stm32l4.dtsi:329 */
			clocks = < &rcc 0x60 0x1000 >;                                              /* in zephyr/dts/arm/st/l4/stm32l4.dtsi:330 */
			st,spi-data-width = "full-4-to-16-bit";                                     /* in zephyr/dts/arm/st/l4/stm32l4.dtsi:331 */
			pinctrl-0 = < &spi1_nss_pa15 &spi1_sck_pb3 &spi1_miso_pb4 &spi1_mosi_pb5 >; /* in application/boards/st/gartennode/gartennode.dts:74 */
			pinctrl-names = "default";                                                  /* in application/boards/st/gartennode/gartennode.dts:76 */
			status = "okay";                                                            /* in application/boards/st/gartennode/gartennode.dts:77 */

			/* node '/soc/spi@40013000/w25q128jv@0' defined in application/boards/st/gartennode/gartennode.dts:78 */
			w25q128jv: w25q128jv@0 {
				compatible = "jedec,spi-nor";      /* in application/boards/st/gartennode/gartennode.dts:79 */
				size = < 0x8000000 >;              /* in application/boards/st/gartennode/gartennode.dts:80 */
				reg = < 0x0 >;                     /* in application/boards/st/gartennode/gartennode.dts:81 */
				spi-max-frequency = < 0x1312d00 >; /* in application/boards/st/gartennode/gartennode.dts:82 */
				hold-gpios = < &gpioa 0x8 0x1 >;   /* in application/boards/st/gartennode/gartennode.dts:83 */
				status = "okay";                   /* in application/boards/st/gartennode/gartennode.dts:84 */
				jedec-id = [ EF 40 18 ];           /* in application/boards/st/gartennode/gartennode.dts:85 */

				/* node '/soc/spi@40013000/w25q128jv@0/partitions' defined in application/boards/st/gartennode/gartennode.dts:87 */
				partitions {
					compatible = "fixed-partitions"; /* in application/boards/st/gartennode/gartennode.dts:88 */
					#address-cells = < 0x1 >;        /* in application/boards/st/gartennode/gartennode.dts:89 */
					#size-cells = < 0x1 >;           /* in application/boards/st/gartennode/gartennode.dts:90 */

					/* node '/soc/spi@40013000/w25q128jv@0/partitions/partition@0' defined in application/boards/st/gartennode/gartennode.dts:92 */
					slot1_partition: partition@0 {
						label = "image-1";     /* in application/boards/st/gartennode/gartennode.dts:93 */
						reg = < 0x0 0x30000 >; /* in application/boards/st/gartennode/gartennode.dts:94 */
					};

					/* node '/soc/spi@40013000/w25q128jv@0/partitions/partition@30000' defined in application/boards/st/gartennode/gartennode.dts:96 */
					scratch_partition: partition@30000 {
						label = "image-scratch";   /* in application/boards/st/gartennode/gartennode.dts:97 */
						reg = < 0x30000 0x30000 >; /* in application/boards/st/gartennode/gartennode.dts:98 */
					};

					/* node '/soc/spi@40013000/w25q128jv@0/partitions/partition@60000' defined in application/boards/st/gartennode/gartennode.dts:100 */
					storage_partition: partition@60000 {
						label = "storage";        /* in application/boards/st/gartennode/gartennode.dts:101 */
						reg = < 0x60000 0x8000 >; /* in application/boards/st/gartennode/gartennode.dts:102 */
					};
				};
			};
		};

		/* node '/soc/timers@40012c00' defined in zephyr/dts/arm/st/l4/stm32l4.dtsi:335 */
		timers1: timers@40012c00 {
			compatible = "st,stm32-timers"; /* in zephyr/dts/arm/st/l4/stm32l4.dtsi:336 */
			reg = < 0x40012c00 0x400 >;     /* in zephyr/dts/arm/st/l4/stm32l4.dtsi:337 */
			clocks = < &rcc 0x60 0x800 >,
			         < &rcc 0xa 0xff >;     /* in zephyr/dts/arm/st/l4/stm32l4.dtsi:338 */
			resets = < &rctl 0x80b >;       /* in zephyr/dts/arm/st/l4/stm32l4.dtsi:340 */
			interrupts = < 0x18 0x0 >,
			             < 0x19 0x0 >,
			             < 0x1a 0x0 >,
			             < 0x1b 0x0 >;      /* in zephyr/dts/arm/st/l4/stm32l4.dtsi:341 */
			interrupt-names = "brk",
			                  "up",
			                  "trgcom",
			                  "cc";         /* in zephyr/dts/arm/st/l4/stm32l4.dtsi:342 */
			st,prescaler = < 0x0 >;         /* in zephyr/dts/arm/st/l4/stm32l4.dtsi:343 */
			status = "disabled";            /* in zephyr/dts/arm/st/l4/stm32l4.dtsi:344 */

			/* node '/soc/timers@40012c00/pwm' defined in zephyr/dts/arm/st/l4/stm32l4.dtsi:346 */
			pwm {
				compatible = "st,stm32-pwm"; /* in zephyr/dts/arm/st/l4/stm32l4.dtsi:347 */
				status = "disabled";         /* in zephyr/dts/arm/st/l4/stm32l4.dtsi:348 */
				#pwm-cells = < 0x3 >;        /* in zephyr/dts/arm/st/l4/stm32l4.dtsi:349 */
			};

			/* node '/soc/timers@40012c00/counter' defined in zephyr/dts/arm/st/l4/stm32l4.dtsi:352 */
			counter {
				compatible = "st,stm32-counter"; /* in zephyr/dts/arm/st/l4/stm32l4.dtsi:353 */
				status = "disabled";             /* in zephyr/dts/arm/st/l4/stm32l4.dtsi:354 */
			};

			/* node '/soc/timers@40012c00/qdec' defined in zephyr/dts/arm/st/l4/stm32l4.dtsi:357 */
			qdec {
				compatible = "st,stm32-qdec";    /* in zephyr/dts/arm/st/l4/stm32l4.dtsi:358 */
				st,input-filter-level = < 0x0 >; /* in zephyr/dts/arm/st/l4/stm32l4.dtsi:359 */
				status = "disabled";             /* in zephyr/dts/arm/st/l4/stm32l4.dtsi:360 */
			};
		};

		/* node '/soc/timers@40000000' defined in zephyr/dts/arm/st/l4/stm32l4.dtsi:364 */
		timers2: timers@40000000 {
			compatible = "st,stm32-timers"; /* in zephyr/dts/arm/st/l4/stm32l4.dtsi:365 */
			reg = < 0x40000000 0x400 >;     /* in zephyr/dts/arm/st/l4/stm32l4.dtsi:366 */
			clocks = < &rcc 0x58 0x1 >,
			         < &rcc 0x9 0xff >;     /* in zephyr/dts/arm/st/l4/stm32l4.dtsi:367 */
			resets = < &rctl 0x700 >;       /* in zephyr/dts/arm/st/l4/stm32l4.dtsi:369 */
			interrupts = < 0x1c 0x0 >;      /* in zephyr/dts/arm/st/l4/stm32l4.dtsi:370 */
			interrupt-names = "global";     /* in zephyr/dts/arm/st/l4/stm32l4.dtsi:371 */
			st,prescaler = < 0x0 >;         /* in zephyr/dts/arm/st/l4/stm32l4.dtsi:372 */
			status = "disabled";            /* in zephyr/dts/arm/st/l4/stm32l4.dtsi:373 */

			/* node '/soc/timers@40000000/pwm' defined in zephyr/dts/arm/st/l4/stm32l4.dtsi:375 */
			pwm {
				compatible = "st,stm32-pwm"; /* in zephyr/dts/arm/st/l4/stm32l4.dtsi:376 */
				status = "disabled";         /* in zephyr/dts/arm/st/l4/stm32l4.dtsi:377 */
				#pwm-cells = < 0x3 >;        /* in zephyr/dts/arm/st/l4/stm32l4.dtsi:378 */
			};

			/* node '/soc/timers@40000000/counter' defined in zephyr/dts/arm/st/l4/stm32l4.dtsi:381 */
			counter {
				compatible = "st,stm32-counter"; /* in zephyr/dts/arm/st/l4/stm32l4.dtsi:382 */
				status = "disabled";             /* in zephyr/dts/arm/st/l4/stm32l4.dtsi:383 */
			};

			/* node '/soc/timers@40000000/qdec' defined in zephyr/dts/arm/st/l4/stm32l4.dtsi:386 */
			qdec {
				compatible = "st,stm32-qdec";    /* in zephyr/dts/arm/st/l4/stm32l4.dtsi:387 */
				st,input-filter-level = < 0x0 >; /* in zephyr/dts/arm/st/l4/stm32l4.dtsi:388 */
				status = "disabled";             /* in zephyr/dts/arm/st/l4/stm32l4.dtsi:389 */
			};
		};

		/* node '/soc/timers@40001000' defined in zephyr/dts/arm/st/l4/stm32l4.dtsi:393 */
		timers6: timers@40001000 {
			compatible = "st,stm32-timers"; /* in zephyr/dts/arm/st/l4/stm32l4.dtsi:394 */
			reg = < 0x40001000 0x400 >;     /* in zephyr/dts/arm/st/l4/stm32l4.dtsi:395 */
			clocks = < &rcc 0x58 0x10 >,
			         < &rcc 0x9 0xff >;     /* in zephyr/dts/arm/st/l4/stm32l4.dtsi:396 */
			resets = < &rctl 0x704 >;       /* in zephyr/dts/arm/st/l4/stm32l4.dtsi:398 */
			interrupts = < 0x36 0x0 >;      /* in zephyr/dts/arm/st/l4/stm32l4.dtsi:399 */
			interrupt-names = "global";     /* in zephyr/dts/arm/st/l4/stm32l4.dtsi:400 */
			st,prescaler = < 0x0 >;         /* in zephyr/dts/arm/st/l4/stm32l4.dtsi:401 */
			status = "disabled";            /* in zephyr/dts/arm/st/l4/stm32l4.dtsi:402 */

			/* node '/soc/timers@40001000/counter' defined in zephyr/dts/arm/st/l4/stm32l4.dtsi:404 */
			counter {
				compatible = "st,stm32-counter"; /* in zephyr/dts/arm/st/l4/stm32l4.dtsi:405 */
				status = "disabled";             /* in zephyr/dts/arm/st/l4/stm32l4.dtsi:406 */
			};
		};

		/* node '/soc/timers@40014000' defined in zephyr/dts/arm/st/l4/stm32l4.dtsi:410 */
		timers15: timers@40014000 {
			compatible = "st,stm32-timers"; /* in zephyr/dts/arm/st/l4/stm32l4.dtsi:411 */
			reg = < 0x40014000 0x400 >;     /* in zephyr/dts/arm/st/l4/stm32l4.dtsi:412 */
			clocks = < &rcc 0x60 0x10000 >,
			         < &rcc 0xa 0xff >;     /* in zephyr/dts/arm/st/l4/stm32l4.dtsi:413 */
			resets = < &rctl 0x810 >;       /* in zephyr/dts/arm/st/l4/stm32l4.dtsi:415 */
			interrupts = < 0x18 0x0 >;      /* in zephyr/dts/arm/st/l4/stm32l4.dtsi:416 */
			interrupt-names = "global";     /* in zephyr/dts/arm/st/l4/stm32l4.dtsi:417 */
			st,prescaler = < 0x0 >;         /* in zephyr/dts/arm/st/l4/stm32l4.dtsi:418 */
			status = "disabled";            /* in zephyr/dts/arm/st/l4/stm32l4.dtsi:419 */

			/* node '/soc/timers@40014000/pwm' defined in zephyr/dts/arm/st/l4/stm32l4.dtsi:421 */
			pwm {
				compatible = "st,stm32-pwm"; /* in zephyr/dts/arm/st/l4/stm32l4.dtsi:422 */
				status = "disabled";         /* in zephyr/dts/arm/st/l4/stm32l4.dtsi:423 */
				#pwm-cells = < 0x3 >;        /* in zephyr/dts/arm/st/l4/stm32l4.dtsi:424 */
			};

			/* node '/soc/timers@40014000/counter' defined in zephyr/dts/arm/st/l4/stm32l4.dtsi:427 */
			counter {
				compatible = "st,stm32-counter"; /* in zephyr/dts/arm/st/l4/stm32l4.dtsi:428 */
				status = "disabled";             /* in zephyr/dts/arm/st/l4/stm32l4.dtsi:429 */
			};
		};

		/* node '/soc/timers@40014400' defined in zephyr/dts/arm/st/l4/stm32l4.dtsi:433 */
		timers16: timers@40014400 {
			compatible = "st,stm32-timers"; /* in zephyr/dts/arm/st/l4/stm32l4.dtsi:434 */
			reg = < 0x40014400 0x400 >;     /* in zephyr/dts/arm/st/l4/stm32l4.dtsi:435 */
			clocks = < &rcc 0x60 0x20000 >,
			         < &rcc 0xa 0xff >;     /* in zephyr/dts/arm/st/l4/stm32l4.dtsi:436 */
			resets = < &rctl 0x811 >;       /* in zephyr/dts/arm/st/l4/stm32l4.dtsi:438 */
			interrupts = < 0x19 0x0 >;      /* in zephyr/dts/arm/st/l4/stm32l4.dtsi:439 */
			interrupt-names = "global";     /* in zephyr/dts/arm/st/l4/stm32l4.dtsi:440 */
			st,prescaler = < 0x0 >;         /* in zephyr/dts/arm/st/l4/stm32l4.dtsi:441 */
			status = "disabled";            /* in zephyr/dts/arm/st/l4/stm32l4.dtsi:442 */

			/* node '/soc/timers@40014400/pwm' defined in zephyr/dts/arm/st/l4/stm32l4.dtsi:444 */
			pwm {
				compatible = "st,stm32-pwm"; /* in zephyr/dts/arm/st/l4/stm32l4.dtsi:445 */
				status = "disabled";         /* in zephyr/dts/arm/st/l4/stm32l4.dtsi:446 */
				#pwm-cells = < 0x3 >;        /* in zephyr/dts/arm/st/l4/stm32l4.dtsi:447 */
			};

			/* node '/soc/timers@40014400/counter' defined in zephyr/dts/arm/st/l4/stm32l4.dtsi:450 */
			counter {
				compatible = "st,stm32-counter"; /* in zephyr/dts/arm/st/l4/stm32l4.dtsi:451 */
				status = "disabled";             /* in zephyr/dts/arm/st/l4/stm32l4.dtsi:452 */
			};
		};

		/* node '/soc/rtc@40002800' defined in zephyr/dts/arm/st/l4/stm32l4.dtsi:456 */
		rtc: rtc@40002800 {
			compatible = "st,stm32-rtc";       /* in zephyr/dts/arm/st/l4/stm32l4.dtsi:457 */
			reg = < 0x40002800 0x400 >;        /* in zephyr/dts/arm/st/l4/stm32l4.dtsi:458 */
			interrupts = < 0x29 0x0 >;         /* in zephyr/dts/arm/st/l4/stm32l4.dtsi:459 */
			prescaler = < 0x8000 >;            /* in zephyr/dts/arm/st/l4/stm32l4.dtsi:461 */
			alarms-count = < 0x2 >;            /* in zephyr/dts/arm/st/l4/stm32l4.dtsi:462 */
			alrm-exti-line = < 0x12 >;         /* in zephyr/dts/arm/st/l4/stm32l4.dtsi:463 */
			clocks = < &rcc 0x58 0x10000000 >,
			         < &rcc 0x3 0x2280090 >;   /* in application/boards/st/gartennode/gartennode.dts:122 */
			status = "okay";                   /* in application/boards/st/gartennode/gartennode.dts:124 */
		};

		/* node '/soc/adc@50040000' defined in zephyr/dts/arm/st/l4/stm32l4.dtsi:467 */
		adc1: adc@50040000 {
			compatible = "st,stm32-adc";                                /* in zephyr/dts/arm/st/l4/stm32l4.dtsi:468 */
			reg = < 0x50040000 0x100 >;                                 /* in zephyr/dts/arm/st/l4/stm32l4.dtsi:469 */
			clocks = < &rcc 0x4c 0x2000 >;                              /* in zephyr/dts/arm/st/l4/stm32l4.dtsi:470 */
			clock-names = "adcx";                                       /* in zephyr/dts/arm/st/l4/stm32l4.dtsi:471 */
			interrupts = < 0x12 0x0 >;                                  /* in zephyr/dts/arm/st/l4/stm32l4.dtsi:472 */
			#io-channel-cells = < 0x1 >;                                /* in zephyr/dts/arm/st/l4/stm32l4.dtsi:473 */
			st,adc-resolutions = < 0xc 0xa 0x8 0x6 >;                   /* in zephyr/dts/arm/st/l4/stm32l4.dtsi:474 */
			sampling-times = < 0x3 0x7 0xd 0x19 0x30 0x5d 0xf8 0x281 >; /* in zephyr/dts/arm/st/l4/stm32l4.dtsi:475 */
			st,adc-sequencer = "programmable";                          /* in zephyr/dts/arm/st/l4/stm32l4.dtsi:476 */
			st,adc-oversampler = "minimal";                             /* in zephyr/dts/arm/st/l4/stm32l4.dtsi:477 */
			st,adc-internal-regulator = "startup-sw-delay";             /* in zephyr/dts/arm/st/l4/stm32l4.dtsi:478 */
			st,adc-has-deep-powerdown;                                  /* in zephyr/dts/arm/st/l4/stm32l4.dtsi:479 */
			st,adc-has-differential-support;                            /* in zephyr/dts/arm/st/l4/stm32l4.dtsi:480 */
			st,adc-has-injected-support;                                /* in zephyr/dts/arm/st/l4/stm32l4.dtsi:481 */
			#address-cells = < 0x1 >;                                   /* in application/boards/gartennode.overlay:63 */
			#size-cells = < 0x0 >;                                      /* in application/boards/gartennode.overlay:64 */
			pinctrl-0 = < &adc1_in8_pa3 >;                              /* in application/boards/gartennode.overlay:67 */
			pinctrl-names = "default";                                  /* in application/boards/gartennode.overlay:68 */
			st,adc-clock-source = "SYNC";                               /* in application/boards/gartennode.overlay:69 */
			st,adc-prescaler = < 0x4 >;                                 /* in application/boards/gartennode.overlay:70 */
			status = "okay";                                            /* in application/boards/gartennode.overlay:71 */
			phandle = < 0x18 >;                                         /* in zephyr/dts/arm/st/l4/stm32l4.dtsi:608 */

			/* node '/soc/adc@50040000/channel@8' defined in application/boards/gartennode.overlay:73 */
			channel@8 {
				reg = < 0x8 >;                         /* in application/boards/gartennode.overlay:74 */
				zephyr,gain = "ADC_GAIN_1";            /* in application/boards/gartennode.overlay:75 */
				zephyr,reference = "ADC_REF_INTERNAL"; /* in application/boards/gartennode.overlay:76 */
				zephyr,acquisition-time = < 0x0 >;     /* in application/boards/gartennode.overlay:77 */
				zephyr,resolution = < 0xc >;           /* in application/boards/gartennode.overlay:78 */
			};
		};

		/* node '/soc/adc@50040100' defined in zephyr/dts/arm/st/l4/stm32l4.dtsi:485 */
		adc2: adc@50040100 {
			compatible = "st,stm32-adc";                                /* in zephyr/dts/arm/st/l4/stm32l4.dtsi:486 */
			reg = < 0x50040100 0x100 >;                                 /* in zephyr/dts/arm/st/l4/stm32l4.dtsi:487 */
			clocks = < &rcc 0x4c 0x2000 >;                              /* in zephyr/dts/arm/st/l4/stm32l4.dtsi:488 */
			clock-names = "adcx";                                       /* in zephyr/dts/arm/st/l4/stm32l4.dtsi:489 */
			interrupts = < 0x12 0x0 >;                                  /* in zephyr/dts/arm/st/l4/stm32l4.dtsi:490 */
			#io-channel-cells = < 0x1 >;                                /* in zephyr/dts/arm/st/l4/stm32l4.dtsi:491 */
			st,adc-resolutions = < 0xc 0xa 0x8 0x6 >;                   /* in zephyr/dts/arm/st/l4/stm32l4.dtsi:492 */
			sampling-times = < 0x3 0x7 0xd 0x19 0x30 0x5d 0xf8 0x281 >; /* in zephyr/dts/arm/st/l4/stm32l4.dtsi:493 */
			st,adc-sequencer = "programmable";                          /* in zephyr/dts/arm/st/l4/stm32l4.dtsi:494 */
			st,adc-oversampler = "minimal";                             /* in zephyr/dts/arm/st/l4/stm32l4.dtsi:495 */
			st,adc-internal-regulator = "startup-sw-delay";             /* in zephyr/dts/arm/st/l4/stm32l4.dtsi:496 */
			st,adc-has-deep-powerdown;                                  /* in zephyr/dts/arm/st/l4/stm32l4.dtsi:497 */
			st,adc-has-differential-support;                            /* in zephyr/dts/arm/st/l4/stm32l4.dtsi:498 */
			st,adc-has-injected-support;                                /* in zephyr/dts/arm/st/l4/stm32l4.dtsi:499 */
			status = "disabled";                                        /* in zephyr/dts/arm/st/l4/stm32l4.dtsi:500 */
		};

		/* node '/soc/dma@40020000' defined in zephyr/dts/arm/st/l4/stm32l4.dtsi:503 */
		dma1: dma@40020000 {
			compatible = "st,stm32-dma-v2";                                             /* in zephyr/dts/arm/st/l4/stm32l4.dtsi:504 */
			#dma-cells = < 0x3 >;                                                       /* in zephyr/dts/arm/st/l4/stm32l4.dtsi:505 */
			reg = < 0x40020000 0x400 >;                                                 /* in zephyr/dts/arm/st/l4/stm32l4.dtsi:506 */
			interrupts = < 0xb 0x0 0xc 0x0 0xd 0x0 0xe 0x0 0xf 0x0 0x10 0x0 0x11 0x0 >; /* in zephyr/dts/arm/st/l4/stm32l4.dtsi:507 */
			clocks = < &rcc 0x48 0x1 >;                                                 /* in zephyr/dts/arm/st/l4/stm32l4.dtsi:508 */
			dma-requests = < 0x7 >;                                                     /* in zephyr/dts/arm/st/l4/stm32l4.dtsi:509 */
			status = "disabled";                                                        /* in zephyr/dts/arm/st/l4/stm32l4.dtsi:510 */
		};

		/* node '/soc/dma@40020400' defined in zephyr/dts/arm/st/l4/stm32l4.dtsi:513 */
		dma2: dma@40020400 {
			compatible = "st,stm32-dma-v2";                                                  /* in zephyr/dts/arm/st/l4/stm32l4.dtsi:514 */
			#dma-cells = < 0x3 >;                                                            /* in zephyr/dts/arm/st/l4/stm32l4.dtsi:515 */
			reg = < 0x40020400 0x400 >;                                                      /* in zephyr/dts/arm/st/l4/stm32l4.dtsi:516 */
			interrupts = < 0x38 0x0 0x39 0x0 0x3a 0x0 0x3b 0x0 0x3c 0x0 0x44 0x0 0x45 0x0 >; /* in zephyr/dts/arm/st/l4/stm32l4.dtsi:517 */
			clocks = < &rcc 0x48 0x2 >;                                                      /* in zephyr/dts/arm/st/l4/stm32l4.dtsi:518 */
			dma-requests = < 0x7 >;                                                          /* in zephyr/dts/arm/st/l4/stm32l4.dtsi:519 */
			status = "disabled";                                                             /* in zephyr/dts/arm/st/l4/stm32l4.dtsi:520 */
			phandle = < 0xf >;                                                               /* in zephyr/dts/arm/st/l4/stm32l4_sai.dtsi:16 */
		};

		/* node '/soc/timers@40007c00' defined in zephyr/dts/arm/st/l4/stm32l4.dtsi:523 */
		lptim1: timers@40007c00 {
			compatible = "st,stm32-lptim";     /* in zephyr/dts/arm/st/l4/stm32l4.dtsi:524 */
			clocks = < &rcc 0x58 0x80000000 >; /* in zephyr/dts/arm/st/l4/stm32l4.dtsi:525 */
			resets = < &rctl 0x71f >;          /* in zephyr/dts/arm/st/l4/stm32l4.dtsi:526 */
			#address-cells = < 0x1 >;          /* in zephyr/dts/arm/st/l4/stm32l4.dtsi:527 */
			#size-cells = < 0x0 >;             /* in zephyr/dts/arm/st/l4/stm32l4.dtsi:528 */
			reg = < 0x40007c00 0x400 >;        /* in zephyr/dts/arm/st/l4/stm32l4.dtsi:529 */
			interrupts = < 0x41 0x1 >;         /* in zephyr/dts/arm/st/l4/stm32l4.dtsi:530 */
			interrupt-names = "wakeup";        /* in zephyr/dts/arm/st/l4/stm32l4.dtsi:531 */
			status = "disabled";               /* in zephyr/dts/arm/st/l4/stm32l4.dtsi:532 */
		};

		/* node '/soc/timers@40009400' defined in zephyr/dts/arm/st/l4/stm32l4.dtsi:535 */
		lptim2: timers@40009400 {
			compatible = "st,stm32-lptim"; /* in zephyr/dts/arm/st/l4/stm32l4.dtsi:536 */
			#address-cells = < 0x1 >;      /* in zephyr/dts/arm/st/l4/stm32l4.dtsi:537 */
			#size-cells = < 0x0 >;         /* in zephyr/dts/arm/st/l4/stm32l4.dtsi:538 */
			reg = < 0x40009400 0x400 >;    /* in zephyr/dts/arm/st/l4/stm32l4.dtsi:539 */
			clocks = < &rcc 0x5c 0x20 >;   /* in zephyr/dts/arm/st/l4/stm32l4.dtsi:540 */
			resets = < &rctl 0x785 >;      /* in zephyr/dts/arm/st/l4/stm32l4.dtsi:541 */
			interrupts = < 0x42 0x1 >;     /* in zephyr/dts/arm/st/l4/stm32l4.dtsi:542 */
			interrupt-names = "wakeup";    /* in zephyr/dts/arm/st/l4/stm32l4.dtsi:543 */
			status = "disabled";           /* in zephyr/dts/arm/st/l4/stm32l4.dtsi:544 */
		};

		/* node '/soc/rng@50060800' defined in zephyr/dts/arm/st/l4/stm32l4.dtsi:547 */
		rng: rng@50060800 {
			compatible = "st,stm32-rng";    /* in zephyr/dts/arm/st/l4/stm32l4.dtsi:548 */
			reg = < 0x50060800 0x400 >;     /* in zephyr/dts/arm/st/l4/stm32l4.dtsi:549 */
			interrupts = < 0x50 0x0 >;      /* in zephyr/dts/arm/st/l4/stm32l4.dtsi:550 */
			status = "disabled";            /* in zephyr/dts/arm/st/l4/stm32l4.dtsi:556 */
			clocks = < &rcc 0x4c 0x40000 >,
			         < &rcc 0x6 0x3a0088 >; /* in zephyr/dts/arm/st/l4/stm32l431.dtsi:42 */
		};

		/* node '/soc/power@40007000' defined in zephyr/dts/arm/st/l4/stm32l4.dtsi:559 */
		pwr: power@40007000 {
			compatible = "st,stm32-pwr"; /* in zephyr/dts/arm/st/l4/stm32l4.dtsi:560 */
			reg = < 0x40007000 0x400 >;  /* in zephyr/dts/arm/st/l4/stm32l4.dtsi:561 */
			status = "disabled";         /* in zephyr/dts/arm/st/l4/stm32l4.dtsi:562 */
			wkup-pins-nb = < 0x5 >;      /* in zephyr/dts/arm/st/l4/stm32l4.dtsi:564 */
			wkup-pins-pol;               /* in zephyr/dts/arm/st/l4/stm32l4.dtsi:565 */
			wkup-pins-pupd;              /* in zephyr/dts/arm/st/l4/stm32l4.dtsi:566 */
			#address-cells = < 0x1 >;    /* in zephyr/dts/arm/st/l4/stm32l4.dtsi:568 */
			#size-cells = < 0x0 >;       /* in zephyr/dts/arm/st/l4/stm32l4.dtsi:569 */

			/* node '/soc/power@40007000/wkup-pin@1' defined in zephyr/dts/arm/st/l4/stm32l4.dtsi:571 */
			wkup-pin@1 {
				reg = < 0x1 >; /* in zephyr/dts/arm/st/l4/stm32l4.dtsi:572 */
			};

			/* node '/soc/power@40007000/wkup-pin@2' defined in zephyr/dts/arm/st/l4/stm32l4.dtsi:575 */
			wkup-pin@2 {
				reg = < 0x2 >; /* in zephyr/dts/arm/st/l4/stm32l4.dtsi:576 */
			};

			/* node '/soc/power@40007000/wkup-pin@3' defined in zephyr/dts/arm/st/l4/stm32l4.dtsi:579 */
			wkup-pin@3 {
				reg = < 0x3 >; /* in zephyr/dts/arm/st/l4/stm32l4.dtsi:580 */
			};

			/* node '/soc/power@40007000/wkup-pin@4' defined in zephyr/dts/arm/st/l4/stm32l4.dtsi:583 */
			wkup-pin@4 {
				reg = < 0x4 >; /* in zephyr/dts/arm/st/l4/stm32l4.dtsi:584 */
			};

			/* node '/soc/power@40007000/wkup-pin@5' defined in zephyr/dts/arm/st/l4/stm32l4.dtsi:587 */
			wkup-pin@5 {
				reg = < 0x5 >; /* in zephyr/dts/arm/st/l4/stm32l4.dtsi:588 */
			};
		};

		/* node '/soc/crc@40023000' defined in zephyr/dts/arm/st/l4/stm32l4.dtsi:592 */
		crc: crc@40023000 {
			compatible = "st,stm32-crc";   /* in zephyr/dts/arm/st/l4/stm32l4.dtsi:593 */
			reg = < 0x40023000 0x400 >;    /* in zephyr/dts/arm/st/l4/stm32l4.dtsi:594 */
			clocks = < &rcc 0x48 0x1000 >; /* in zephyr/dts/arm/st/l4/stm32l4.dtsi:595 */
			resets = < &rctl 0x50c >;      /* in zephyr/dts/arm/st/l4/stm32l4.dtsi:596 */
			status = "disabled";           /* in zephyr/dts/arm/st/l4/stm32l4.dtsi:597 */
		};

		/* node '/soc/sai1@40015404' defined in zephyr/dts/arm/st/l4/stm32l4_sai.dtsi:9 */
		sai1_a: sai1@40015404 {
			compatible = "st,stm32-sai";      /* in zephyr/dts/arm/st/l4/stm32l4_sai.dtsi:10 */
			#address-cells = < 0x1 >;         /* in zephyr/dts/arm/st/l4/stm32l4_sai.dtsi:11 */
			#size-cells = < 0x0 >;            /* in zephyr/dts/arm/st/l4/stm32l4_sai.dtsi:12 */
			reg = < 0x40015404 0x20 >;        /* in zephyr/dts/arm/st/l4/stm32l4_sai.dtsi:13 */
			clocks = < &rcc 0x60 0x200000 >,
			         < &rcc 0xe 0x360088 >;   /* in zephyr/dts/arm/st/l4/stm32l4_sai.dtsi:14 */
			dmas = < &dma2 0x1 0x1 0x22800 >; /* in zephyr/dts/arm/st/l4/stm32l4_sai.dtsi:16 */
			status = "disabled";              /* in zephyr/dts/arm/st/l4/stm32l4_sai.dtsi:18 */
		};

		/* node '/soc/sai1@40015424' defined in zephyr/dts/arm/st/l4/stm32l4_sai.dtsi:21 */
		sai1_b: sai1@40015424 {
			compatible = "st,stm32-sai";      /* in zephyr/dts/arm/st/l4/stm32l4_sai.dtsi:22 */
			#address-cells = < 0x1 >;         /* in zephyr/dts/arm/st/l4/stm32l4_sai.dtsi:23 */
			#size-cells = < 0x0 >;            /* in zephyr/dts/arm/st/l4/stm32l4_sai.dtsi:24 */
			reg = < 0x40015424 0x20 >;        /* in zephyr/dts/arm/st/l4/stm32l4_sai.dtsi:25 */
			clocks = < &rcc 0x60 0x200000 >,
			         < &rcc 0xe 0x360088 >;   /* in zephyr/dts/arm/st/l4/stm32l4_sai.dtsi:26 */
			dmas = < &dma2 0x2 0x1 0x22800 >; /* in zephyr/dts/arm/st/l4/stm32l4_sai.dtsi:28 */
			status = "disabled";              /* in zephyr/dts/arm/st/l4/stm32l4_sai.dtsi:30 */
		};

		/* node '/soc/i2c@40005800' defined in zephyr/dts/arm/st/l4/stm32l431.dtsi:46 */
		i2c2: i2c@40005800 {
			compatible = "st,stm32-i2c-v2";  /* in zephyr/dts/arm/st/l4/stm32l431.dtsi:47 */
			#address-cells = < 0x1 >;        /* in zephyr/dts/arm/st/l4/stm32l431.dtsi:48 */
			#size-cells = < 0x0 >;           /* in zephyr/dts/arm/st/l4/stm32l431.dtsi:49 */
			reg = < 0x40005800 0x400 >;      /* in zephyr/dts/arm/st/l4/stm32l431.dtsi:50 */
			clocks = < &rcc 0x58 0x400000 >; /* in zephyr/dts/arm/st/l4/stm32l431.dtsi:51 */
			clock-frequency = < 0x186a0 >;   /* in zephyr/dts/arm/st/l4/stm32l431.dtsi:52 */
			interrupts = < 0x21 0x0 >,
			             < 0x22 0x0 >;       /* in zephyr/dts/arm/st/l4/stm32l431.dtsi:53 */
			interrupt-names = "event",
			                  "error";       /* in zephyr/dts/arm/st/l4/stm32l431.dtsi:54 */
			status = "disabled";             /* in zephyr/dts/arm/st/l4/stm32l431.dtsi:55 */
			phandle = < 0x1c >;              /* in zephyr/dts/arm/st/l4/stm32l431.dtsi:138 */
		};

		/* node '/soc/spi@40003800' defined in zephyr/dts/arm/st/l4/stm32l431.dtsi:58 */
		spi2: spi@40003800 {
			compatible = "st,stm32-spi-fifo",
			             "st,stm32-spi";            /* in zephyr/dts/arm/st/l4/stm32l431.dtsi:59 */
			#address-cells = < 0x1 >;               /* in zephyr/dts/arm/st/l4/stm32l431.dtsi:60 */
			#size-cells = < 0x0 >;                  /* in zephyr/dts/arm/st/l4/stm32l431.dtsi:61 */
			reg = < 0x40003800 0x400 >;             /* in zephyr/dts/arm/st/l4/stm32l431.dtsi:62 */
			clocks = < &rcc 0x58 0x4000 >;          /* in zephyr/dts/arm/st/l4/stm32l431.dtsi:63 */
			interrupts = < 0x24 0x5 >;              /* in zephyr/dts/arm/st/l4/stm32l431.dtsi:64 */
			st,spi-data-width = "full-4-to-16-bit"; /* in zephyr/dts/arm/st/l4/stm32l431.dtsi:65 */
			status = "disabled";                    /* in zephyr/dts/arm/st/l4/stm32l431.dtsi:66 */
		};

		/* node '/soc/spi@40003c00' defined in zephyr/dts/arm/st/l4/stm32l431.dtsi:69 */
		spi3: spi@40003c00 {
			compatible = "st,stm32-spi-fifo",
			             "st,stm32-spi";            /* in zephyr/dts/arm/st/l4/stm32l431.dtsi:70 */
			#address-cells = < 0x1 >;               /* in zephyr/dts/arm/st/l4/stm32l431.dtsi:71 */
			#size-cells = < 0x0 >;                  /* in zephyr/dts/arm/st/l4/stm32l431.dtsi:72 */
			reg = < 0x40003c00 0x400 >;             /* in zephyr/dts/arm/st/l4/stm32l431.dtsi:73 */
			clocks = < &rcc 0x58 0x8000 >;          /* in zephyr/dts/arm/st/l4/stm32l431.dtsi:74 */
			interrupts = < 0x33 0x5 >;              /* in zephyr/dts/arm/st/l4/stm32l431.dtsi:75 */
			st,spi-data-width = "full-4-to-16-bit"; /* in zephyr/dts/arm/st/l4/stm32l431.dtsi:76 */
			status = "disabled";                    /* in zephyr/dts/arm/st/l4/stm32l431.dtsi:77 */
		};

		/* node '/soc/serial@40004800' defined in zephyr/dts/arm/st/l4/stm32l431.dtsi:80 */
		usart3: serial@40004800 {
			compatible = "st,stm32-usart",
			             "st,stm32-uart";   /* in zephyr/dts/arm/st/l4/stm32l431.dtsi:81 */
			reg = < 0x40004800 0x400 >;     /* in zephyr/dts/arm/st/l4/stm32l431.dtsi:82 */
			clocks = < &rcc 0x58 0x40000 >; /* in zephyr/dts/arm/st/l4/stm32l431.dtsi:83 */
			resets = < &rctl 0x712 >;       /* in zephyr/dts/arm/st/l4/stm32l431.dtsi:84 */
			interrupts = < 0x27 0x0 >;      /* in zephyr/dts/arm/st/l4/stm32l431.dtsi:85 */
			status = "disabled";            /* in zephyr/dts/arm/st/l4/stm32l431.dtsi:86 */
		};

		/* node '/soc/timers@40001400' defined in zephyr/dts/arm/st/l4/stm32l431.dtsi:89 */
		timers7: timers@40001400 {
			compatible = "st,stm32-timers"; /* in zephyr/dts/arm/st/l4/stm32l431.dtsi:90 */
			reg = < 0x40001400 0x400 >;     /* in zephyr/dts/arm/st/l4/stm32l431.dtsi:91 */
			clocks = < &rcc 0x58 0x20 >,
			         < &rcc 0x9 0xff >;     /* in zephyr/dts/arm/st/l4/stm32l431.dtsi:92 */
			resets = < &rctl 0x705 >;       /* in zephyr/dts/arm/st/l4/stm32l431.dtsi:94 */
			interrupts = < 0x37 0x0 >;      /* in zephyr/dts/arm/st/l4/stm32l431.dtsi:95 */
			interrupt-names = "global";     /* in zephyr/dts/arm/st/l4/stm32l431.dtsi:96 */
			st,prescaler = < 0x0 >;         /* in zephyr/dts/arm/st/l4/stm32l431.dtsi:97 */
			status = "disabled";            /* in zephyr/dts/arm/st/l4/stm32l431.dtsi:98 */

			/* node '/soc/timers@40001400/counter' defined in zephyr/dts/arm/st/l4/stm32l431.dtsi:100 */
			counter {
				compatible = "st,stm32-counter"; /* in zephyr/dts/arm/st/l4/stm32l431.dtsi:101 */
				status = "disabled";             /* in zephyr/dts/arm/st/l4/stm32l431.dtsi:102 */
			};
		};

		/* node '/soc/can@40006400' defined in zephyr/dts/arm/st/l4/stm32l431.dtsi:106 */
		can1: can@40006400 {
			compatible = "st,stm32-bxcan";               /* in zephyr/dts/arm/st/l4/stm32l431.dtsi:107 */
			reg = < 0x40006400 0x400 >;                  /* in zephyr/dts/arm/st/l4/stm32l431.dtsi:108 */
			clocks = < &rcc 0x58 0x2000000 >;            /* in zephyr/dts/arm/st/l4/stm32l431.dtsi:109 */
			interrupts = < 0x13 0x0 >,
			             < 0x14 0x0 >,
			             < 0x15 0x0 >,
			             < 0x16 0x0 >;                   /* in zephyr/dts/arm/st/l4/stm32l431.dtsi:110 */
			interrupt-names = "TX",
			                  "RX0",
			                  "RX1",
			                  "SCE";                     /* in zephyr/dts/arm/st/l4/stm32l431.dtsi:111 */
			pinctrl-0 = < &can1_rx_pa11 &can1_tx_pa12 >; /* in application/boards/st/gartennode/gartennode.dts:116 */
			pinctrl-names = "default";                   /* in application/boards/st/gartennode/gartennode.dts:117 */
			status = "okay";                             /* in application/boards/st/gartennode/gartennode.dts:118 */
		};

		/* node '/soc/sdmmc@40012800' defined in zephyr/dts/arm/st/l4/stm32l431.dtsi:115 */
		sdmmc1: sdmmc@40012800 {
			compatible = "st,stm32-sdmmc";  /* in zephyr/dts/arm/st/l4/stm32l431.dtsi:116 */
			reg = < 0x40012800 0x400 >;     /* in zephyr/dts/arm/st/l4/stm32l431.dtsi:117 */
			clocks = < &rcc 0x60 0x400 >,
			         < &rcc 0x6 0x3a0088 >; /* in zephyr/dts/arm/st/l4/stm32l431.dtsi:118 */
			resets = < &rctl 0x80a >;       /* in zephyr/dts/arm/st/l4/stm32l431.dtsi:120 */
			interrupts = < 0x31 0x0 >;      /* in zephyr/dts/arm/st/l4/stm32l431.dtsi:121 */
			status = "disabled";            /* in zephyr/dts/arm/st/l4/stm32l431.dtsi:122 */
		};

		/* node '/soc/dac@40007400' defined in zephyr/dts/arm/st/l4/stm32l431.dtsi:125 */
		dac1: dac@40007400 {
			compatible = "st,stm32-dac";       /* in zephyr/dts/arm/st/l4/stm32l431.dtsi:126 */
			reg = < 0x40007400 0x400 >;        /* in zephyr/dts/arm/st/l4/stm32l431.dtsi:127 */
			clocks = < &rcc 0x58 0x20000000 >; /* in zephyr/dts/arm/st/l4/stm32l431.dtsi:128 */
			#io-channel-cells = < 0x1 >;       /* in zephyr/dts/arm/st/l4/stm32l431.dtsi:129 */
			status = "disabled";               /* in zephyr/dts/arm/st/l4/stm32l431.dtsi:130 */
		};
	};

	/* node '/cpus' defined in zephyr/dts/arm/st/l4/stm32l4.dtsi:30 */
	cpus {
		#address-cells = < 0x1 >; /* in zephyr/dts/arm/st/l4/stm32l4.dtsi:31 */
		#size-cells = < 0x0 >;    /* in zephyr/dts/arm/st/l4/stm32l4.dtsi:32 */

		/* node '/cpus/cpu@0' defined in zephyr/dts/arm/st/l4/stm32l4.dtsi:34 */
		cpu0: cpu@0 {
			device_type = "cpu";                         /* in zephyr/dts/arm/st/l4/stm32l4.dtsi:35 */
			compatible = "arm,cortex-m4f";               /* in zephyr/dts/arm/st/l4/stm32l4.dtsi:36 */
			reg = < 0x0 >;                               /* in zephyr/dts/arm/st/l4/stm32l4.dtsi:37 */
			cpu-power-states = < &stop0 &stop1 &stop2 >; /* in zephyr/dts/arm/st/l4/stm32l4.dtsi:38 */
		};

		/* node '/cpus/power-states' defined in zephyr/dts/arm/st/l4/stm32l4.dtsi:41 */
		power-states {

			/* node '/cpus/power-states/state0' defined in zephyr/dts/arm/st/l4/stm32l4.dtsi:42 */
			stop0: state0 {
				compatible = "zephyr,power-state";    /* in zephyr/dts/arm/st/l4/stm32l4.dtsi:43 */
				power-state-name = "suspend-to-idle"; /* in zephyr/dts/arm/st/l4/stm32l4.dtsi:44 */
				substate-id = < 0x1 >;                /* in zephyr/dts/arm/st/l4/stm32l4.dtsi:45 */
				min-residency-us = < 0x1f4 >;         /* in zephyr/dts/arm/st/l4/stm32l4.dtsi:46 */
				phandle = < 0x12 >;                   /* in zephyr/dts/arm/st/l4/stm32l4.dtsi:38 */
			};

			/* node '/cpus/power-states/state1' defined in zephyr/dts/arm/st/l4/stm32l4.dtsi:49 */
			stop1: state1 {
				compatible = "zephyr,power-state";    /* in zephyr/dts/arm/st/l4/stm32l4.dtsi:50 */
				power-state-name = "suspend-to-idle"; /* in zephyr/dts/arm/st/l4/stm32l4.dtsi:51 */
				substate-id = < 0x2 >;                /* in zephyr/dts/arm/st/l4/stm32l4.dtsi:52 */
				min-residency-us = < 0x2bc >;         /* in zephyr/dts/arm/st/l4/stm32l4.dtsi:53 */
				phandle = < 0x13 >;                   /* in zephyr/dts/arm/st/l4/stm32l4.dtsi:38 */
			};

			/* node '/cpus/power-states/state2' defined in zephyr/dts/arm/st/l4/stm32l4.dtsi:56 */
			stop2: state2 {
				compatible = "zephyr,power-state";    /* in zephyr/dts/arm/st/l4/stm32l4.dtsi:57 */
				power-state-name = "suspend-to-idle"; /* in zephyr/dts/arm/st/l4/stm32l4.dtsi:58 */
				substate-id = < 0x3 >;                /* in zephyr/dts/arm/st/l4/stm32l4.dtsi:59 */
				min-residency-us = < 0x3e8 >;         /* in zephyr/dts/arm/st/l4/stm32l4.dtsi:60 */
				phandle = < 0x14 >;                   /* in zephyr/dts/arm/st/l4/stm32l4.dtsi:38 */
			};
		};
	};

	/* node '/memory@20000000' defined in zephyr/dts/arm/st/l4/stm32l4.dtsi:65 */
	sram0: memory@20000000 {
		compatible = "zephyr,memory-region",
		             "mmio-sram";            /* in zephyr/dts/arm/st/l4/stm32l4.dtsi:66 */
		zephyr,memory-region = "SRAM0";      /* in zephyr/dts/arm/st/l4/stm32l4.dtsi:67 */
		reg = < 0x20000000 0x10000 >;        /* in application/boards/st/gartennode/stm32l431Xc.dtsi:12 */
	};

	/* node '/clocks' defined in zephyr/dts/arm/st/l4/stm32l4.dtsi:70 */
	clocks {

		/* node '/clocks/clk-hse' defined in zephyr/dts/arm/st/l4/stm32l4.dtsi:71 */
		clk_hse: clk-hse {
			#clock-cells = < 0x0 >;            /* in zephyr/dts/arm/st/l4/stm32l4.dtsi:72 */
			compatible = "st,stm32-hse-clock"; /* in zephyr/dts/arm/st/l4/stm32l4.dtsi:73 */
			status = "disabled";               /* in zephyr/dts/arm/st/l4/stm32l4.dtsi:74 */
		};

		/* node '/clocks/clk-hsi' defined in zephyr/dts/arm/st/l4/stm32l4.dtsi:77 */
		clk_hsi: clk-hsi {
			#clock-cells = < 0x0 >;         /* in zephyr/dts/arm/st/l4/stm32l4.dtsi:78 */
			compatible = "fixed-clock";     /* in zephyr/dts/arm/st/l4/stm32l4.dtsi:79 */
			clock-frequency = < 0xf42400 >; /* in zephyr/dts/arm/st/l4/stm32l4.dtsi:80 */
			status = "okay";                /* in application/boards/st/gartennode/gartennode.dts:45 */
			phandle = < 0x15 >;             /* in application/boards/st/gartennode/gartennode.dts:54 */
		};

		/* node '/clocks/clk-msi' defined in zephyr/dts/arm/st/l4/stm32l4.dtsi:84 */
		clk_msi: clk-msi {
			#clock-cells = < 0x0 >;            /* in zephyr/dts/arm/st/l4/stm32l4.dtsi:85 */
			compatible = "st,stm32-msi-clock"; /* in zephyr/dts/arm/st/l4/stm32l4.dtsi:86 */
			msi-range = < 0x6 >;               /* in zephyr/dts/arm/st/l4/stm32l4.dtsi:87 */
			status = "disabled";               /* in zephyr/dts/arm/st/l4/stm32l4.dtsi:88 */
		};

		/* node '/clocks/clk-lse' defined in zephyr/dts/arm/st/l4/stm32l4.dtsi:91 */
		clk_lse: clk-lse {
			#clock-cells = < 0x0 >;            /* in zephyr/dts/arm/st/l4/stm32l4.dtsi:92 */
			compatible = "st,stm32-lse-clock"; /* in zephyr/dts/arm/st/l4/stm32l4.dtsi:93 */
			clock-frequency = < 0x8000 >;      /* in zephyr/dts/arm/st/l4/stm32l4.dtsi:94 */
			driving-capability = < 0x0 >;      /* in zephyr/dts/arm/st/l4/stm32l4.dtsi:95 */
			status = "disabled";               /* in zephyr/dts/arm/st/l4/stm32l4.dtsi:96 */
		};

		/* node '/clocks/clk-lsi' defined in zephyr/dts/arm/st/l4/stm32l4.dtsi:99 */
		clk_lsi: clk-lsi {
			#clock-cells = < 0x0 >;       /* in zephyr/dts/arm/st/l4/stm32l4.dtsi:100 */
			compatible = "fixed-clock";   /* in zephyr/dts/arm/st/l4/stm32l4.dtsi:101 */
			clock-frequency = < 0x7d00 >; /* in zephyr/dts/arm/st/l4/stm32l4.dtsi:102 */
			status = "okay";              /* in application/boards/st/gartennode/gartennode.dts:41 */
		};

		/* node '/clocks/pll' defined in zephyr/dts/arm/st/l4/stm32l4.dtsi:106 */
		pll: pll {
			#clock-cells = < 0x0 >;              /* in zephyr/dts/arm/st/l4/stm32l4.dtsi:107 */
			compatible = "st,stm32l4-pll-clock"; /* in zephyr/dts/arm/st/l4/stm32l4.dtsi:108 */
			div-m = < 0x1 >;                     /* in application/boards/st/gartennode/gartennode.dts:49 */
			mul-n = < 0x14 >;                    /* in application/boards/st/gartennode/gartennode.dts:50 */
			div-p = < 0x7 >;                     /* in application/boards/st/gartennode/gartennode.dts:51 */
			div-q = < 0x2 >;                     /* in application/boards/st/gartennode/gartennode.dts:52 */
			div-r = < 0x4 >;                     /* in application/boards/st/gartennode/gartennode.dts:53 */
			clocks = < &clk_hsi >;               /* in application/boards/st/gartennode/gartennode.dts:54 */
			status = "okay";                     /* in application/boards/st/gartennode/gartennode.dts:55 */
			phandle = < 0x3 >;                   /* in application/boards/st/gartennode/gartennode.dts:59 */
		};

		/* node '/clocks/pllsai1' defined in zephyr/dts/arm/st/l4/stm32l4.dtsi:112 */
		pllsai1: pllsai1 {
			#clock-cells = < 0x0 >;              /* in zephyr/dts/arm/st/l4/stm32l4.dtsi:113 */
			compatible = "st,stm32l4-pll-clock"; /* in zephyr/dts/arm/st/l4/stm32l4.dtsi:114 */
			status = "disabled";                 /* in zephyr/dts/arm/st/l4/stm32l4.dtsi:115 */
		};

		/* node '/clocks/clk-hsi48' defined in zephyr/dts/arm/st/l4/stm32l431.dtsi:12 */
		clk_hsi48: clk-hsi48 {
			#clock-cells = < 0x0 >;          /* in zephyr/dts/arm/st/l4/stm32l431.dtsi:13 */
			compatible = "fixed-clock";      /* in zephyr/dts/arm/st/l4/stm32l431.dtsi:14 */
			clock-frequency = < 0x2dc6c00 >; /* in zephyr/dts/arm/st/l4/stm32l431.dtsi:15 */
			status = "disabled";             /* in zephyr/dts/arm/st/l4/stm32l431.dtsi:16 */
		};
	};

	/* node '/mcos' defined in zephyr/dts/arm/st/l4/stm32l4.dtsi:119 */
	mcos {

		/* node '/mcos/mco1' defined in zephyr/dts/arm/st/l4/stm32l4.dtsi:120 */
		mco1: mco1 {
			compatible = "st,stm32-clock-mco"; /* in zephyr/dts/arm/st/l4/stm32l4.dtsi:121 */
			clock-names = "clksel";            /* in zephyr/dts/arm/st/l4/stm32l4.dtsi:122 */
			status = "disabled";               /* in zephyr/dts/arm/st/l4/stm32l4.dtsi:123 */
		};
	};

	/* node '/dietemp' defined in zephyr/dts/arm/st/l4/stm32l4.dtsi:601 */
	die_temp: dietemp {
		compatible = "st,stm32-temp-cal"; /* in zephyr/dts/arm/st/l4/stm32l4.dtsi:602 */
		nvmem-cells = < &ts_cal1_otp >,
		              < &ts_cal2_otp >;   /* in zephyr/dts/arm/st/l4/stm32l4.dtsi:603 */
		nvmem-cell-names = "TS_CAL1",
		                   "TS_CAL2";     /* in zephyr/dts/arm/st/l4/stm32l4.dtsi:604 */
		ts-cal1-temp = < 0x1e >;          /* in zephyr/dts/arm/st/l4/stm32l4.dtsi:605 */
		ts-cal2-temp = < 0x82 >;          /* in zephyr/dts/arm/st/l4/stm32l4.dtsi:606 */
		ts-cal-vrefanalog = < 0xbb8 >;    /* in zephyr/dts/arm/st/l4/stm32l4.dtsi:607 */
		io-channels = < &adc1 0x11 >;     /* in zephyr/dts/arm/st/l4/stm32l4.dtsi:608 */
		status = "disabled";              /* in zephyr/dts/arm/st/l4/stm32l4.dtsi:609 */
	};

	/* node '/vref' defined in zephyr/dts/arm/st/l4/stm32l4.dtsi:612 */
	vref: vref {
		compatible = "st,stm32-vref";   /* in zephyr/dts/arm/st/l4/stm32l4.dtsi:613 */
		nvmem-cells = < &vrefint_otp >; /* in zephyr/dts/arm/st/l4/stm32l4.dtsi:614 */
		vrefint-cal-mv = < 0xbb8 >;     /* in zephyr/dts/arm/st/l4/stm32l4.dtsi:615 */
		io-channels = < &adc1 0x0 >;    /* in zephyr/dts/arm/st/l4/stm32l4.dtsi:616 */
		status = "disabled";            /* in zephyr/dts/arm/st/l4/stm32l4.dtsi:617 */
	};

	/* node '/vbat' defined in zephyr/dts/arm/st/l4/stm32l4.dtsi:620 */
	vbat: vbat {
		compatible = "st,stm32-vbat"; /* in zephyr/dts/arm/st/l4/stm32l4.dtsi:621 */
		ratio = < 0x3 >;              /* in zephyr/dts/arm/st/l4/stm32l4.dtsi:622 */
		io-channels = < &adc1 0x12 >; /* in zephyr/dts/arm/st/l4/stm32l4.dtsi:623 */
		status = "disabled";          /* in zephyr/dts/arm/st/l4/stm32l4.dtsi:624 */
	};

	/* node '/smbus1' defined in zephyr/dts/arm/st/l4/stm32l4.dtsi:627 */
	smbus1: smbus1 {
		compatible = "st,stm32-smbus"; /* in zephyr/dts/arm/st/l4/stm32l4.dtsi:628 */
		#address-cells = < 0x1 >;      /* in zephyr/dts/arm/st/l4/stm32l4.dtsi:629 */
		#size-cells = < 0x0 >;         /* in zephyr/dts/arm/st/l4/stm32l4.dtsi:630 */
		i2c = < &i2c1 >;               /* in zephyr/dts/arm/st/l4/stm32l4.dtsi:631 */
		status = "disabled";           /* in zephyr/dts/arm/st/l4/stm32l4.dtsi:632 */
	};

	/* node '/smbus3' defined in zephyr/dts/arm/st/l4/stm32l4.dtsi:635 */
	smbus3: smbus3 {
		compatible = "st,stm32-smbus"; /* in zephyr/dts/arm/st/l4/stm32l4.dtsi:636 */
		#address-cells = < 0x1 >;      /* in zephyr/dts/arm/st/l4/stm32l4.dtsi:637 */
		#size-cells = < 0x0 >;         /* in zephyr/dts/arm/st/l4/stm32l4.dtsi:638 */
		i2c = < &i2c3 >;               /* in zephyr/dts/arm/st/l4/stm32l4.dtsi:639 */
		status = "disabled";           /* in zephyr/dts/arm/st/l4/stm32l4.dtsi:640 */
	};

	/* node '/smbus2' defined in zephyr/dts/arm/st/l4/stm32l431.dtsi:134 */
	smbus2: smbus2 {
		compatible = "st,stm32-smbus"; /* in zephyr/dts/arm/st/l4/stm32l431.dtsi:135 */
		#address-cells = < 0x1 >;      /* in zephyr/dts/arm/st/l4/stm32l431.dtsi:136 */
		#size-cells = < 0x0 >;         /* in zephyr/dts/arm/st/l4/stm32l431.dtsi:137 */
		i2c = < &i2c2 >;               /* in zephyr/dts/arm/st/l4/stm32l431.dtsi:138 */
		status = "disabled";           /* in zephyr/dts/arm/st/l4/stm32l431.dtsi:139 */
	};

	/* node '/leds' defined in application/boards/st/gartennode/gartennode.dts:19 */
	leds: leds {
		compatible = "gpio-leds"; /* in application/boards/st/gartennode/gartennode.dts:20 */

		/* node '/leds/led_0' defined in application/boards/st/gartennode/gartennode.dts:21 */
		green_led: led_0 {
			gpios = < &gpioc 0xf 0x0 >; /* in application/boards/st/gartennode/gartennode.dts:22 */
			label = "User LD1";         /* in application/boards/st/gartennode/gartennode.dts:23 */
		};
	};

	/* node '/zephyr,user' defined in application/boards/gartennode.overlay:8 */
	zephyr,user {
		io-channels = < &adc1 0x8 >; /* in application/boards/gartennode.overlay:9 */
	};

	/* node '/pressure_sw' defined in application/boards/gartennode.overlay:12 */
	pressure_sw: pressure_sw {
		compatible = "power-switch"; /* in application/boards/gartennode.overlay:13 */
		gpios = < &gpioa 0x0 0x20 >; /* in application/boards/gartennode.overlay:15 */
		status = "okay";             /* in application/boards/gartennode.overlay:16 */
	};

	/* node '/ultrasonic_sw' defined in application/boards/gartennode.overlay:19 */
	ultrasonic_sw: ultrasonic_sw {
		compatible = "power-switch"; /* in application/boards/gartennode.overlay:20 */
		gpios = < &gpioa 0x1 0x20 >; /* in application/boards/gartennode.overlay:22 */
		status = "okay";             /* in application/boards/gartennode.overlay:23 */
	};

	/* node '/temperature_sw' defined in application/boards/gartennode.overlay:26 */
	temperature_sw: temperature_sw {
		compatible = "power-switch"; /* in application/boards/gartennode.overlay:27 */
		gpios = < &gpioa 0x2 0x20 >; /* in application/boards/gartennode.overlay:29 */
		status = "okay";             /* in application/boards/gartennode.overlay:30 */
	};

	/* node '/HC-SR04' defined in application/boards/gartennode.overlay:36 */
	us0: HC-SR04 {
		compatible = "hc-sr04";             /* in application/boards/gartennode.overlay:37 */
		trigger-gpios = < &gpioa 0x4 0x0 >; /* in application/boards/gartennode.overlay:38 */
		echo-gpios = < &gpioa 0x5 0x20 >;   /* in application/boards/gartennode.overlay:39 */
		status = "okay";                    /* in application/boards/gartennode.overlay:40 */
	};

	/* node '/w1-zephyr-gpio-0' defined in application/boards/gartennode.overlay:42 */
	w1_0: w1-zephyr-gpio-0 {
		compatible = "zephyr,w1-gpio"; /* in application/boards/gartennode.overlay:43 */
		gpios = < &gpioa 0x6 0x16 >;   /* in application/boards/gartennode.overlay:44 */
		status = "okay";               /* in application/boards/gartennode.overlay:45 */

		/* node '/w1-zephyr-gpio-0/ds18b200' defined in application/boards/gartennode.overlay:47 */
		temp_0: ds18b200 {
			compatible = "maxim,ds18b20"; /* in application/boards/gartennode.overlay:48 */
			family-code = < 0x28 >;       /* in application/boards/gartennode.overlay:49 */
			resolution = < 0xc >;         /* in application/boards/gartennode.overlay:50 */
			status = "okay";              /* in application/boards/gartennode.overlay:51 */
		};

		/* node '/w1-zephyr-gpio-0/ds18b201' defined in application/boards/gartennode.overlay:53 */
		temp_1: ds18b201 {
			compatible = "maxim,ds18b20"; /* in application/boards/gartennode.overlay:54 */
			family-code = < 0x28 >;       /* in application/boards/gartennode.overlay:55 */
			resolution = < 0xc >;         /* in application/boards/gartennode.overlay:56 */
			status = "okay";              /* in application/boards/gartennode.overlay:57 */
		};
	};
};
